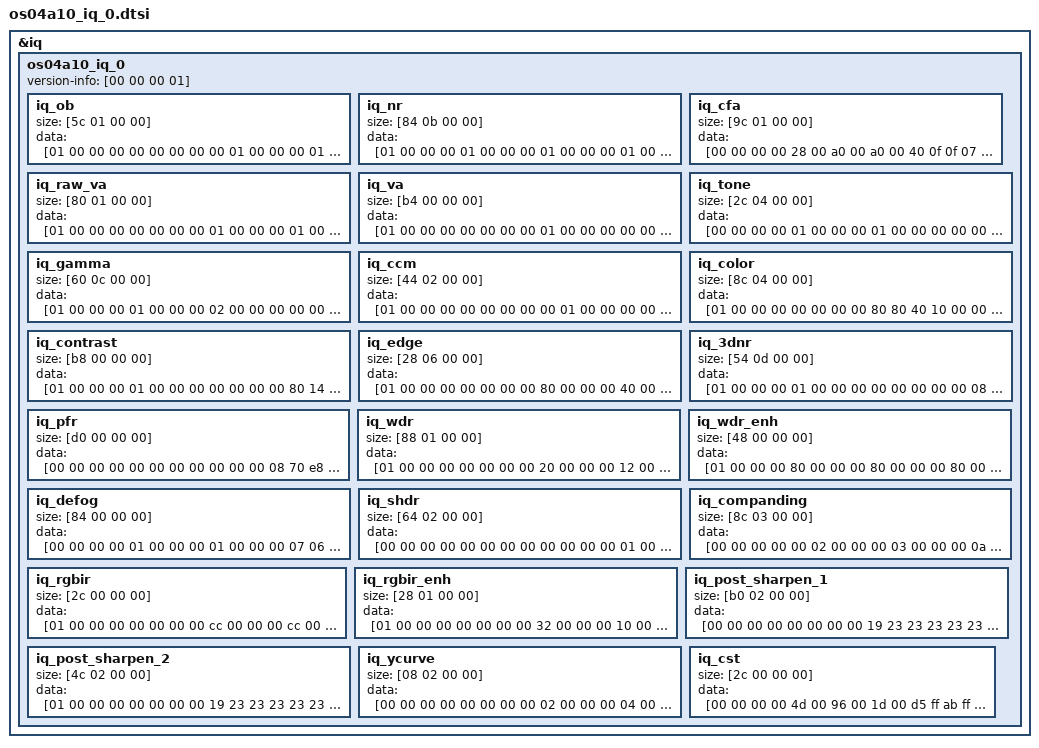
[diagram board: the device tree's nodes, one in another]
/*
 * Novatek Ltd. NVT98538 ISP part of dts
 */

&iq {
	os04a10_iq_0 {
		version-info = [00 00 00 01];
		iq_ob {
			size = [5c 01 00 00];
			data = [01 00 00 00 00 00 00 00 00 01 00 00 00 01 00 00 00 01 00 00 00 01 00 00 00 01 00 00 00 01 00 00 00 01 00 00 00 01 00 00 00 01 00 00 00 01 00 00 00 01 00 00 00 01 00 00 00 01 00 00 00 01 00 00 00 01 00 00 00 01 00 00 00 01 00 00 00 01 00 00 00 01 00 00 00 01 00 00 00 01 00 00 00 01 00 00 00 01 00 00 00 01 00 00 00 01 00 00 00 01 00 00 00 01 00 00 00 01 00 00 00 01 00 00 00 01 00 00 00 01 00 00 00 01 00 00 00 01 00 00 00 01 00 00 00 01 00 00 00 01 00 00 00 01 00 00 00 01 00 00 00 01 00 00 00 01 00 00 00 01 00 00 00 01 00 00 00 01 00 00 00 01 00 00 00 01 00 00 00 01 00 00 00 01 00 00 00 01 00 00 00 01 00 00 00 01 00 00 00 01 00 00 00 01 00 00 00 01 00 00 00 01 00 00 00 01 00 00 00 01 00 00 00 01 00 00 00 01 00 00 00 01 00 00 00 01 00 00 00 01 00 00 00 01 00 00 00 01 00 00 00 01 00 00 00 01 00 00 00 01 00 00 00 01 00 00 00 01 00 00 00 01 00 00 00 01 00 00 00 01 00 00 00 01 00 00 00 01 00 00 00 01 00 00 00 01 00 00 00 01 00 00 00 01 00 00 00 01 00 00 00 01 00 00 00 01 00 00 00 01 00 00 00 01 00 00 00 01 00 00 00 01 00 00 00 01 00 00];
		};
		iq_nr {
			size = [84 0b 00 00];
			data = [01 00 00 00 01 00 00 00 01 00 00 00 01 00 00 00 01 00 00 00 00 00 00 00 00 01 ff 00 00 00 00 00 00 00 00 00 ff 0f ff 0f ff 0f ff 0f ff 0f ff 0f ff 0f ff 0f ff 0f ff 0f 00 01 80 00 00 00 00 00 00 00 00 00 00 00 00 00 00 00 00 00 00 00 00 00 00 00 00 00 00 00 00 00 00 00 00 00 00 00 00 00 00 00 00 00 00 00 00 00 00 00 00 00 00 00 00 00 00 00 00 00 00 00 00 00 00 00 00 00 00 00 00 00 00 00 00 00 00 00 00 00 00 00 00 00 00 00 00 00 00 00 00 00 00 00 00 00 00 00 00 00 00 00 00 00 80 00 00 00 64 00 00 00 00 00 00 00 00 00 00 00 00 02 08 50 1e 02 01 03 01 01 00 00 02 00 00 00 02 00 00 00 00 01 ff 00 00 00 00 00 00 00 00 00 c6 02 0c 04 af 06 3d 09 41 0f c6 02 0c 04 af 06 3d 09 41 0f 00 00 80 00 00 00 00 00 00 00 00 00 01 00 01 00 01 00 02 00 00 00 02 00 02 00 03 00 04 00 04 00 04 00 05 00 05 00 06 00 06 00 06 00 06 00 07 00 07 00 07 00 08 00 00 00 00 00 03 00 03 00 03 00 06 00 00 00 02 00 02 00 03 00 04 00 04 00 04 00 05 00 05 00 06 00 06 00 06 00 06 00 07 00 07 00 07 00 08 00 00 00 40 00 80 00 00 00 64 00 00 00 00 00 00 00 00 00 00 00 00 02 08 50 00 04 06 03 01 01 00 00 00 00 00 00 00 00 00 00 00 01 ff 00 00 00 00 00 00 00 00 00 c6 02 0c 04 af 06 3d 09 41 0f c6 02 0c 04 af 06 3d 09 41 0f 00 00 80 00 00 00 00 00 00 00 02 00 02 00 03 00 04 00 05 00 00 00 02 00 03 00 04 00 04 00 05 00 05 00 06 00 06 00 07 00 07 00 07 00 08 00 08 00 08 00 09 00 09 00 00 00 06 00 06 00 09 00 0c 00 0f 00 00 00 02 00 03 00 04 00 04 00 05 00 05 00 06 00 06 00 07 00 07 00 07 00 08 00 08 00 08 00 09 00 09 00 00 00 40 00 80 00 00 00 64 00 00 00 00 00 00 00 00 00 00 00 00 02 08 50 00 06 0a 03 01 01 00 00 00 00 00 00 00 00 00 00 00 01 ff 00 00 00 00 00 00 00 00 00 c6 02 0c 04 af 06 3d 09 41 0f c6 02 0c 04 af 06 3d 09 41 0f 00 00 80 00 00 00 00 00 00 00 02 00 03 00 04 00 05 00 07 00 00 00 03 00 04 00 05 00 06 00 07 00 07 00 08 00 09 00 09 00 0a 00 0a 00 0b 00 0b 00 0b 00 0c 00 0c 00 00 00 06 00 09 00 0c 00 0f 00 15 00 00 00 03 00 04 00 05 00 06 00 07 00 07 00 08 00 09 00 09 00 0a 00 0a 00 0b 00 0b 00 0b 00 0c 00 0c 00 00 00 40 00 80 00 00 00 64 00 00 00 00 00 00 00 00 00 00 00 00 02 08 50 00 06 0a 03 01 01 00 00 00 00 00 00 00 00 00 00 00 01 ff 00 00 00 00 00 00 00 00 00 c6 02 0c 04 af 06 3d 09 41 0f c6 02 0c 04 af 06 3d 09 41 0f 09 00 80 00 00 00 00 00 00 00 02 00 03 00 04 00 05 00 07 00 00 00 04 00 05 00 06 00 08 00 08 00 09 00 0a 00 0b 00 0c 00 0c 00 0d 00 0d 00 0e 00 0e 00 0f 00 10 00 00 00 06 00 09 00 0c 00 0f 00 15 00 00 00 04 00 05 00 06 00 08 00 08 00 09 00 0a 00 0b 00 0c 00 0c 00 0d 00 0d 00 0e 00 0e 00 0f 00 10 00 00 00 20 00 80 00 00 00 64 00 00 00 00 00 00 00 00 00 00 00 00 02 08 50 00 06 0a 03 01 01 00 00 00 00 00 00 00 00 00 00 00 01 ff 00 00 00 00 00 00 00 00 00 c6 02 0c 04 af 06 3d 09 41 0f c6 02 0c 04 af 06 3d 09 41 0f 09 00 80 00 00 00 00 00 00 00 03 00 04 00 05 00 06 00 09 00 00 00 05 00 07 00 09 00 0b 00 0c 00 0d 00 0e 00 0f 00 10 00 11 00 12 00 13 00 14 00 14 00 15 00 16 00 00 00 09 00 0c 00 0f 00 12 00 1b 00 00 00 05 00 07 00 09 00 0b 00 0c 00 0d 00 0e 00 0f 00 10 00 11 00 12 00 13 00 14 00 14 00 15 00 16 00 00 00 20 00 6e 00 00 00 64 00 00 00 00 00 00 00 00 00 00 00 00 02 08 50 00 08 0c 03 01 01 00 00 00 00 00 00 00 00 00 00 00 01 ff 00 00 00 00 00 00 00 00 00 c6 02 0c 04 af 06 3d 09 41 0f c6 02 0c 04 af 06 3d 09 41 0f 09 00 80 00 00 00 00 00 00 00 04 00 06 00 07 00 08 00 0c 00 00 00 07 00 0a 00 0c 00 0e 00 10 00 11 00 13 00 14 00 15 00 16 00 17 00 18 00 19 00 1a 00 1b 00 1c 00 00 00 0c 00 12 00 15 00 18 00 24 00 00 00 07 00 0a 00 0c 00 0e 00 10 00 11 00 13 00 14 00 15 00 16 00 17 00 18 00 19 00 1a 00 1b 00 1c 00 00 00 20 00 6e 00 00 00 64 00 00 00 00 00 00 00 00 00 00 00 00 02 08 50 00 0a 10 03 01 01 00 00 00 00 00 00 01 00 00 00 00 01 ff 00 00 00 00 00 00 00 00 00 c6 02 0c 04 af 06 3d 09 41 0f c6 02 0c 04 af 06 3d 09 41 0f 09 00 80 00 00 00 00 00 00 00 06 00 09 00 0b 00 0c 00 12 00 00 00 05 00 0a 00 14 00 17 00 19 00 1c 00 1e 00 20 00 22 00 24 00 26 00 28 00 29 00 2b 00 2c 00 2e 00 00 00 12 00 1b 00 21 00 24 00 36 00 00 00 05 00 0a 00 14 00 17 00 19 00 1c 00 1e 00 20 00 22 00 24 00 26 00 28 00 29 00 2b 00 2c 00 2e 00 00 00 20 00 6e 00 00 00 64 00 00 00 00 00 00 00 00 00 00 00 00 02 08 50 00 0a 10 03 01 01 00 00 00 00 00 00 01 00 00 00 00 01 ff 00 00 00 00 00 00 00 00 00 c6 02 0c 04 af 06 3d 09 41 0f c6 02 0c 04 af 06 3d 09 41 0f 09 00 80 00 00 00 00 00 00 00 06 00 09 00 0b 00 0c 00 12 00 00 00 10 00 16 00 1b 00 20 00 23 00 27 00 2a 00 2d 00 30 00 32 00 35 00 37 00 39 00 3b 00 3d 00 40 00 00 00 13 00 1b 00 21 00 26 00 36 00 00 00 10 00 16 00 1b 00 20 00 23 00 27 00 2a 00 2d 00 30 00 32 00 35 00 37 00 39 00 3b 00 3d 00 40 00 00 00 20 00 6e 00 00 00 64 00 00 00 00 00 00 00 00 00 00 00 00 02 08 50 00 0a 10 03 01 01 00 00 01 00 00 00 02 00 00 00 00 01 ff 00 00 00 00 00 00 00 00 00 c6 02 0c 04 af 06 3d 09 41 0f c6 02 0c 04 af 06 3d 09 41 0f 09 00 80 00 00 00 00 00 00 00 0b 00 10 00 13 00 16 00 20 00 00 00 0f 00 1e 00 25 00 2b 00 30 00 34 00 39 00 3d 00 40 00 44 00 47 00 4a 00 4d 00 50 00 53 00 56 00 00 00 21 00 30 00 3b 00 42 00 60 00 00 00 0f 00 1e 00 25 00 2b 00 30 00 34 00 39 00 3d 00 40 00 44 00 47 00 4a 00 4d 00 50 00 53 00 56 00 00 00 20 00 64 00 00 00 64 00 00 00 00 00 00 00 00 00 00 00 00 05 14 28 02 0c 14 03 01 01 00 00 01 00 00 00 02 00 00 00 00 01 ff 00 00 00 00 00 00 00 00 00 c6 02 0c 04 af 06 3d 09 41 0f c6 02 0c 04 af 06 3d 09 41 0f 09 00 80 00 00 00 00 00 00 00 11 00 18 00 1e 00 23 00 31 00 00 00 12 00 19 00 1f 00 24 00 28 00 2c 00 2f 00 32 00 36 00 38 00 3b 00 3e 00 40 00 43 00 45 00 48 00 00 00 34 00 4a 00 5b 00 69 00 95 00 00 00 12 00 19 00 1f 00 24 00 28 00 2c 00 2f 00 32 00 36 00 38 00 3b 00 3e 00 40 00 43 00 45 00 48 00 08 00 14 00 40 00 00 00 90 01 00 00 00 00 00 00 00 00 00 00 00 0a 28 50 08 1c 20 03 01 01 00 00 01 00 00 00 02 00 00 00 00 01 ff 00 00 00 00 00 00 00 00 00 c6 02 0c 04 af 06 3d 09 41 0f c6 02 0c 04 af 06 3d 09 41 0f 5a 00 80 00 00 00 00 00 00 00 1a 00 25 00 2d 00 34 00 4a 00 00 00 17 00 20 00 28 00 2e 00 33 00 38 00 3d 00 41 00 45 00 49 00 4c 00 50 00 53 00 56 00 59 00 5c 00 00 00 49 00 67 00 7e 00 92 00 cf 00 00 00 1e 00 2a 00 33 00 3c 00 43 00 49 00 4f 00 54 00 5a 00 5e 00 63 00 67 00 6c 00 70 00 74 00 78 00 0a 00 0a 00 20 00 00 00 64 00 00 00 00 00 00 00 00 00 00 00 00 0a 28 50 0a 20 20 03 01 01 00 00 01 00 00 00 02 00 00 00 00 01 ff 00 00 00 00 00 00 00 00 00 c6 02 0c 04 af 06 3d 09 41 0f c6 02 0c 04 af 06 3d 09 41 0f 5a 00 80 00 00 00 00 00 00 00 2f 00 42 00 51 00 5e 00 85 00 00 00 24 00 34 00 3f 00 49 00 52 00 5a 00 61 00 68 00 6e 00 74 00 7a 00 7f 00 84 00 89 00 8e 00 93 00 00 00 8d 00 c7 00 f4 00 1a 01 8f 01 00 00 24 00 34 00 3f 00 49 00 52 00 5a 00 61 00 68 00 6e 00 74 00 7a 00 7f 00 84 00 89 00 8e 00 93 00 0c 00 0a 00 20 00 00 00 64 00 00 00 00 00 00 00 00 00 00 00 00 28 a0 f0 00 20 20 03 01 01 00 00 01 00 00 00 02 00 00 00 00 01 ff 00 00 00 00 00 00 00 00 00 c6 02 0c 04 af 06 3d 09 41 0f c6 02 0c 04 af 06 3d 09 41 0f 5a 00 80 00 00 00 00 00 00 00 2e 00 42 00 51 00 5d 00 84 00 00 00 32 00 47 00 57 00 65 00 71 00 7c 00 86 00 8f 00 98 00 a0 00 a8 00 af 00 b7 00 be 00 c4 00 cb 00 00 00 8a 00 c6 00 f3 00 17 01 8c 01 00 00 32 00 47 00 57 00 65 00 71 00 7c 00 86 00 8f 00 98 00 a0 00 a8 00 af 00 b7 00 be 00 c4 00 cb 00 0e 00 0a 00 20 00 00 00 64 00 00 00 00 00 00 00 00 00 00 00 00 02 08 50 00 20 20 03 01 01 00 00 01 00 00 00 02 00 00 00 00 01 ff 00 00 00 00 00 00 00 00 00 9a 01 53 02 d6 03 90 05 2e 09 9a 01 53 02 d6 03 90 05 2e 09 09 00 80 00 00 00 00 00 00 00 11 00 18 00 1e 00 23 00 31 00 00 00 30 00 43 00 53 00 60 00 6b 00 75 00 7e 00 87 00 90 00 97 00 9f 00 a6 00 ad 00 b3 00 b9 00 c0 00 00 00 33 00 48 00 5a 00 69 00 93 00 00 00 30 00 43 00 53 00 60 00 6b 00 75 00 7e 00 87 00 90 00 97 00 9f 00 a6 00 ad 00 b3 00 b9 00 c0 00 00 00 20 00 20 00 00 00 64 00 00 00 00 00 00 00 00 00 00 00 00 02 08 50 00 20 20 03 01 01 00 00 01 00 00 00 02 00 00 00 00 01 ff 00 00 00 00 00 00 00 00 00 9a 01 53 02 d6 03 90 05 2e 09 9a 01 53 02 d6 03 90 05 2e 09 09 00 80 00 00 00 00 00 00 00 11 00 18 00 1e 00 23 00 31 00 00 00 30 00 43 00 53 00 60 00 6b 00 75 00 7e 00 87 00 90 00 97 00 9f 00 a6 00 ad 00 b3 00 b9 00 c0 00 00 00 33 00 48 00 5a 00 69 00 93 00 00 00 30 00 43 00 53 00 60 00 6b 00 75 00 7e 00 87 00 90 00 97 00 9f 00 a6 00 ad 00 b3 00 b9 00 c0 00 00 00 20 00 20 00 00 00 64 00 00 00 00 00 00 00 00 00 00 00 00 02 08 50 00 20 20 03 01 01 00 00 01 00 00 00 02 00 00 00 00 01 ff 00 00 00 00 00 00 00 00 00 9a 01 53 02 d6 03 90 05 2e 09 9a 01 53 02 d6 03 90 05 2e 09 09 00 80 00 00 00 00 00 00 00 11 00 18 00 1e 00 23 00 31 00 00 00 30 00 43 00 53 00 60 00 6b 00 75 00 7e 00 87 00 90 00 97 00 9f 00 a6 00 ad 00 b3 00 b9 00 c0 00 00 00 33 00 48 00 5a 00 69 00 93 00 00 00 30 00 43 00 53 00 60 00 6b 00 75 00 7e 00 87 00 90 00 97 00 9f 00 a6 00 ad 00 b3 00 b9 00 c0 00 00 00 20 00 20 00 00 00 64 00 00 00 00 00 00 00 00 00 00 00 00 02 08 50 00 20 20 03 01 01 00 00 01 00 00 00 02 00 00 00];
		};
		iq_cfa {
			size = [9c 01 00 00];
			data = [00 00 00 00 28 00 a0 00 a0 00 40 0f 0f 07 04 03 02 02 01 01 01 01 00 00 00 00 00 00 28 00 a0 00 a0 00 40 0f 0f 07 04 03 02 02 01 01 01 01 00 00 00 00 00 00 28 00 a0 00 a0 00 40 0f 0f 07 04 03 02 02 01 01 01 01 00 00 00 00 00 00 28 00 a0 00 a0 00 40 0f 0f 07 04 03 02 02 01 01 01 01 00 00 00 00 00 00 28 00 a0 00 a0 00 40 0f 0f 07 04 03 02 02 01 01 01 01 00 00 00 00 00 00 28 00 a0 00 a0 00 40 0f 0f 07 04 03 02 02 01 01 01 01 00 00 00 00 00 00 28 00 a0 00 a0 00 40 0f 0f 07 04 03 02 02 01 01 01 01 00 00 00 00 00 00 28 00 a0 00 a0 00 40 0f 0f 07 04 03 02 02 01 01 01 01 00 00 00 00 00 00 28 00 a0 00 a0 00 40 0f 0f 07 04 03 02 02 01 01 01 01 00 00 00 00 00 00 28 00 a0 00 a0 00 40 0f 0f 07 04 03 02 02 01 01 01 01 00 00 00 00 00 00 28 00 a0 00 a0 00 40 0f 0f 07 04 03 02 02 01 01 01 01 00 00 00 00 00 00 28 00 a0 00 a0 00 20 08 08 03 02 01 01 01 00 00 00 00 00 00 00 00 00 00 28 00 a0 00 a0 00 20 08 08 03 02 01 01 01 00 00 00 00 00 00 00 00 00 00 28 00 a0 00 a0 00 40 0f 0f 07 04 03 02 02 01 01 01 01 00 00 00 00 00 00 28 00 a0 00 a0 00 40 0f 0f 07 04 03 02 02 01 01 01 01 00 00 00 00 00 00 28 00 a0 00 a0 00 40 0f 0f 07 04 03 02 02 01 01 01 01 00 00 00 00 00 00 28 00 a0 00 a0 00 40 0f 0f 07 04 03 02 02 01 01 01 01 00 00 00 00 00 00];
		};
		iq_raw_va {
			size = [80 01 00 00];
			data = [01 00 00 00 00 00 00 00 01 00 00 00 01 00 00 00 00 00 00 00 ff ff 00 00 03 00 00 00 01 00 00 00 00 00 00 00 02 00 00 00 ff ff 00 00 03 0a 96 ff ff 02 06 10 00 00 00 00 96 00 00 00 2c 00 a9 fe ca 00 06 00 00 00 2c 00 45 fe df 00 08 00 00 00 29 00 ae 00 00 00 08 00 00 00 00 00 00 00 2c 00 a9 fe ca 00 06 00 00 00 2c 00 45 fe df 00 08 00 00 00 29 00 ae 00 00 00 08 00 00 00 00 00 00 00 00 00 00 00 00 00 00 00 00 00 00 00 00 00 00 00 00 00 00 00 00 00 00 00 00 00 00 00 00 00 00 00 00 00 00 00 00 00 00 00 00 00 00 00 00 00 00 00 00 00 00 00 00 00 00 00 00 00 00 00 00 00 00 00 00 00 00 00 00 00 00 00 00 00 00 00 00 00 00 00 01 00 00 00 00 00 00 00 01 00 00 00 00 00 00 00 01 00 00 00 00 00 00 00 01 00 00 00 00 00 00 00 01 00 00 00 00 00 00 00 01 00 00 00 00 00 00 00 02 00 00 00 00 00 00 00 02 00 00 00 00 00 00 00 02 00 00 00 00 00 00 00 02 00 00 00 00 00 00 00 02 00 00 00 00 00 00 00 02 00 00 00 00 00 00 00 03 00 00 00 00 00 00 00 03 00 00 00 00 00 00 00 03 00 00 00 00 00 00 00 03 00 00 00 00 00 00 00 03 00 00 00 00 00 00 00 03 00 00 00 00 00 00 00 03 00 00 00 00 00 00 00 03 00 00 00 00 00 00 00 03 00 00 00 00 00 00 00 03 00 00 00 00 00 00 00];
		};
		iq_va {
			size = [b4 00 00 00];
			data = [01 00 00 00 00 00 00 00 01 00 00 00 00 00 ff 00 02 00 00 00 00 00 00 00 02 00 ff 00 03 0a 96 ff ff 02 06 10 00 00 00 00 96 00 00 00 00 00 00 00 00 00 00 00 00 00 00 00 00 00 00 00 00 00 00 00 00 00 00 00 00 00 00 00 00 00 00 00 00 00 00 00 00 00 00 00 00 00 00 00 00 00 00 00 00 00 00 00 00 00 00 00 00 00 00 00 00 00 00 00 00 00 00 00 00 00 00 00 00 00 00 00 00 00 00 00 00 00 00 00 00 00 00 00 00 00 00 00 00 00 00 00 00 00 00 00 00 00 00 00 00 00 00 00 00 00 00 00 00 00 00 00 00 00 00 00 00 00 00 00 00 00 00 00 00 00 00 00 00 00 00 00];
		};
		iq_tone {
			size = [2c 04 00 00];
			data = [00 00 00 00 01 00 00 00 01 00 00 00 00 00 00 00 00 00 00 00 00 00 00 00 8e 00 1c 01 aa 01 38 02 a9 02 1b 03 8c 03 fd 03 59 04 b5 04 11 05 6d 05 ba 05 06 06 53 06 9f 06 e0 06 20 07 61 07 a1 07 d8 07 0f 08 46 08 7d 08 ad 08 dd 08 0c 09 3c 09 66 09 90 09 b9 09 e3 09 08 0a 2d 0a 51 0a 76 0a 97 0a b7 0a d8 0a f8 0a 15 0b 33 0b 50 0b 6d 0b 88 0b a2 0b bd 0b d7 0b ef 0b 07 0c 1e 0c 36 0c 4c 0c 62 0c 77 0c 8d 0c a1 0c b5 0c c9 0c dd 0c ef 0c 02 0d 14 0d 26 0d 26 0d 6a 0d a8 0d e3 0d 1a 0e 4e 0e 7e 0e ac 0e d8 0e 02 0f 2a 0f 50 0f 75 0f 99 0f bc 0f de 0f ff 0f 00 00 00 00 00 00 00 00 e0 00 9e 01 43 02 d5 02 58 03 cf 03 3b 04 9e 04 03 05 5d 05 ab 05 ed 05 12 06 37 06 59 06 7a 06 93 06 ac 06 c5 06 de 06 f7 06 0f 07 27 07 40 07 58 07 6f 07 87 07 9f 07 b6 07 cd 07 e4 07 fc 07 13 08 2a 08 41 08 58 08 6e 08 85 08 9c 08 b2 08 c9 08 df 08 f5 08 0c 09 22 09 38 09 4e 09 64 09 7a 09 90 09 a6 09 bc 09 d2 09 e8 09 fe 09 13 0a 29 0a 3f 0a 54 0a 6a 0a 80 0a 95 0a ab 0a c0 0a c0 0a 16 0b 6c 0b c1 0b 16 0c 6a 0c bf 0c 13 0d 67 0d ba 0d 0e 0e 61 0e b4 0e 07 0f 5a 0f ad 0f ff 0f 19 00 00 00 00 00 57 01 59 02 27 03 d4 03 68 04 e9 04 5c 05 c4 05 2a 06 84 06 d1 06 12 07 35 07 57 07 77 07 96 07 ac 07 c2 07 d8 07 ef 07 04 08 1a 08 30 08 46 08 5b 08 70 08 85 08 9b 08 af 08 c4 08 d8 08 ed 08 01 09 16 09 2a 09 3e 09 52 09 66 09 7a 09 8e 09 a2 09 b6 09 c9 09 dd 09 f1 09 04 0a 18 0a 2b 0a 3f 0a 52 0a 66 0a 79 0a 8c 0a a0 0a b3 0a c6 0a d9 0a ec 0a ff 0a 13 0b 26 0b 39 0b 4c 0b 5f 0b 5f 0b aa 0b f6 0b 41 0c 8c 0c d6 0c 21 0d 6b 0d b5 0d ff 0d 48 0e 92 0e db 0e 24 0f 6e 0f b7 0f ff 0f 32 00 00 00 00 00 1e 02 69 03 58 04 14 05 ad 05 30 06 a2 06 06 07 67 07 bc 07 04 08 41 08 60 08 7e 08 9b 08 b6 08 c9 08 dd 08 f0 08 04 09 17 09 2a 09 3d 09 50 09 62 09 75 09 87 09 9a 09 ac 09 bd 09 cf 09 e1 09 f3 09 04 0a 16 0a 27 0a 39 0a 4a 0a 5b 0a 6c 0a 7e 0a 8f 0a a0 0a b1 0a c2 0a d3 0a e4 0a f5 0a 05 0b 16 0b 27 0b 38 0b 48 0b 59 0b 6a 0b 7a 0b 8b 0b 9c 0b ac 0b bd 0b cd 0b de 0b ee 0b fe 0b fe 0b 40 0c 81 0c c2 0c 03 0d 43 0d 84 0d c4 0d 04 0e 44 0e 83 0e c3 0e 03 0f 42 0f 81 0f c0 0f ff 0f 4b 00 00 00 00 00 69 02 c7 03 bb 04 77 05 11 06 92 06 01 07 64 07 c2 07 15 08 5b 08 96 08 b4 08 d1 08 ed 08 07 09 19 09 2c 09 3f 09 51 09 63 09 76 09 88 09 9a 09 ab 09 bd 09 ce 09 e0 09 f1 09 02 0a 13 0a 25 0a 36 0a 46 0a 57 0a 68 0a 79 0a 89 0a 9a 0a aa 0a bb 0a cb 0a db 0a ec 0a fc 0a 0c 0b 1c 0b 2c 0b 3d 0b 4d 0b 5d 0b 6d 0b 7d 0b 8d 0b 9d 0b ac 0b bc 0b cc 0b dc 0b ec 0b fc 0b 0b 0c 1b 0c 2b 0c 2b 0c 69 0c a8 0c e6 0c 24 0d 62 0d 9f 0d dd 0d 1a 0e 57 0e 94 0e d1 0e 0d 0f 4a 0f 87 0f c3 0f ff 0f 64 00 00 00 00 00 22 03 9b 04 93 05 4d 06 e1 06 5d 07 c7 07 23 08 7b 08 c8 08 0a 09 41 09 5c 09 77 09 90 09 a8 09 b9 09 ca 09 dc 09 ed 09 fd 09 0e 0a 1e 0a 2f 0a 3f 0a 4e 0a 5e 0a 6e 0a 7d 0a 8d 0a 9d 0a ad 0a bc 0a cb 0a db 0a ea 0a f9 0a 08 0b 17 0b 26 0b 35 0b 44 0b 53 0b 62 0b 70 0b 7f 0b 8e 0b 9c 0b ab 0b ba 0b c8 0b d7 0b e5 0b f4 0b 02 0c 11 0c 1f 0c 2e 0c 3c 0c 4a 0c 59 0c 67 0c 75 0c 84 0c 84 0c bd 0c f5 0c 2e 0d 66 0d 9e 0d d6 0d 0e 0e 46 0e 7d 0e b5 0e ec 0e 23 0f 5b 0f 92 0f c9 0f ff 0f 06 00 00 00 32 00 00 00 04 00 00 00 32 00 00 00 02 00 00 00 32 00 00 00 01 00 00 00 32 00 00 00 00 00 00 00 32 00 00 00];
		};
		iq_gamma {
			size = [60 0c 00 00];
			data = [01 00 00 00 01 00 00 00 02 00 00 00 00 00 00 00 25 00 00 00 49 00 00 00 6b 00 00 00 8b 00 00 00 a9 00 00 00 c6 00 00 00 e1 00 00 00 f1 00 00 00 01 01 00 00 11 01 00 00 21 01 00 00 30 01 00 00 3e 01 00 00 4d 01 00 00 5b 01 00 00 68 01 00 00 75 01 00 00 82 01 00 00 8f 01 00 00 9b 01 00 00 a6 01 00 00 b1 01 00 00 bc 01 00 00 c7 01 00 00 d1 01 00 00 db 01 00 00 e4 01 00 00 ed 01 00 00 f6 01 00 00 fe 01 00 00 06 02 00 00 0d 02 00 00 14 02 00 00 1b 02 00 00 22 02 00 00 29 02 00 00 30 02 00 00 36 02 00 00 3d 02 00 00 44 02 00 00 4b 02 00 00 52 02 00 00 59 02 00 00 5f 02 00 00 66 02 00 00 6d 02 00 00 73 02 00 00 7a 02 00 00 80 02 00 00 87 02 00 00 8d 02 00 00 93 02 00 00 9a 02 00 00 a0 02 00 00 a6 02 00 00 ac 02 00 00 b3 02 00 00 b9 02 00 00 bf 02 00 00 c5 02 00 00 cb 02 00 00 d1 02 00 00 d7 02 00 00 dd 02 00 00 e3 02 00 00 e8 02 00 00 ee 02 00 00 f4 02 00 00 fa 02 00 00 ff 02 00 00 04 03 00 00 09 03 00 00 0e 03 00 00 13 03 00 00 18 03 00 00 1d 03 00 00 21 03 00 00 26 03 00 00 2b 03 00 00 30 03 00 00 35 03 00 00 3a 03 00 00 3e 03 00 00 43 03 00 00 48 03 00 00 4d 03 00 00 51 03 00 00 56 03 00 00 5b 03 00 00 5f 03 00 00 64 03 00 00 68 03 00 00 6d 03 00 00 72 03 00 00 76 03 00 00 7b 03 00 00 7f 03 00 00 84 03 00 00 88 03 00 00 8c 03 00 00 91 03 00 00 95 03 00 00 99 03 00 00 9e 03 00 00 a2 03 00 00 a6 03 00 00 ab 03 00 00 af 03 00 00 b3 03 00 00 b7 03 00 00 bb 03 00 00 bf 03 00 00 c4 03 00 00 c8 03 00 00 cc 03 00 00 d0 03 00 00 d4 03 00 00 d8 03 00 00 dc 03 00 00 e0 03 00 00 e4 03 00 00 e8 03 00 00 eb 03 00 00 ef 03 00 00 f3 03 00 00 f7 03 00 00 fb 03 00 00 ff 03 00 00 00 00 00 00 00 00 00 00 08 00 00 00 10 00 00 00 18 00 00 00 20 00 00 00 28 00 00 00 30 00 00 00 38 00 00 00 40 00 00 00 48 00 00 00 50 00 00 00 58 00 00 00 60 00 00 00 68 00 00 00 70 00 00 00 78 00 00 00 80 00 00 00 88 00 00 00 90 00 00 00 98 00 00 00 a0 00 00 00 a8 00 00 00 b0 00 00 00 b8 00 00 00 c0 00 00 00 c8 00 00 00 d0 00 00 00 d8 00 00 00 e0 00 00 00 e8 00 00 00 f0 00 00 00 f8 00 00 00 00 01 00 00 08 01 00 00 10 01 00 00 18 01 00 00 20 01 00 00 28 01 00 00 30 01 00 00 38 01 00 00 40 01 00 00 48 01 00 00 50 01 00 00 58 01 00 00 60 01 00 00 68 01 00 00 70 01 00 00 78 01 00 00 80 01 00 00 88 01 00 00 90 01 00 00 98 01 00 00 a0 01 00 00 a8 01 00 00 b0 01 00 00 b8 01 00 00 c0 01 00 00 c8 01 00 00 d0 01 00 00 d8 01 00 00 e0 01 00 00 e8 01 00 00 f0 01 00 00 f7 01 00 00 ff 01 00 00 07 02 00 00 0f 02 00 00 17 02 00 00 1f 02 00 00 27 02 00 00 2f 02 00 00 37 02 00 00 3f 02 00 00 47 02 00 00 4f 02 00 00 57 02 00 00 5f 02 00 00 67 02 00 00 6f 02 00 00 77 02 00 00 7f 02 00 00 87 02 00 00 8f 02 00 00 97 02 00 00 9f 02 00 00 a7 02 00 00 af 02 00 00 b7 02 00 00 bf 02 00 00 c7 02 00 00 cf 02 00 00 d7 02 00 00 df 02 00 00 e7 02 00 00 ef 02 00 00 f7 02 00 00 ff 02 00 00 07 03 00 00 0f 03 00 00 17 03 00 00 1f 03 00 00 27 03 00 00 2f 03 00 00 37 03 00 00 3f 03 00 00 47 03 00 00 4f 03 00 00 57 03 00 00 5f 03 00 00 67 03 00 00 6f 03 00 00 77 03 00 00 7f 03 00 00 87 03 00 00 8f 03 00 00 97 03 00 00 9f 03 00 00 a7 03 00 00 af 03 00 00 b7 03 00 00 bf 03 00 00 c7 03 00 00 cf 03 00 00 d7 03 00 00 df 03 00 00 e7 03 00 00 ef 03 00 00 f7 03 00 00 ff 03 00 00 19 00 00 00 00 00 00 00 22 00 00 00 36 00 00 00 47 00 00 00 57 00 00 00 65 00 00 00 73 00 00 00 80 00 00 00 8c 00 00 00 98 00 00 00 a4 00 00 00 b0 00 00 00 bb 00 00 00 c6 00 00 00 d1 00 00 00 dc 00 00 00 e7 00 00 00 f1 00 00 00 fc 00 00 00 06 01 00 00 10 01 00 00 1b 01 00 00 25 01 00 00 2f 01 00 00 39 01 00 00 43 01 00 00 4d 01 00 00 57 01 00 00 60 01 00 00 6a 01 00 00 74 01 00 00 7d 01 00 00 87 01 00 00 90 01 00 00 9a 01 00 00 a3 01 00 00 ac 01 00 00 b6 01 00 00 bf 01 00 00 c8 01 00 00 d1 01 00 00 da 01 00 00 e3 01 00 00 ec 01 00 00 f5 01 00 00 fd 01 00 00 06 02 00 00 0f 02 00 00 17 02 00 00 20 02 00 00 28 02 00 00 30 02 00 00 39 02 00 00 41 02 00 00 49 02 00 00 51 02 00 00 59 02 00 00 61 02 00 00 69 02 00 00 71 02 00 00 78 02 00 00 80 02 00 00 88 02 00 00 8f 02 00 00 97 02 00 00 9e 02 00 00 a5 02 00 00 ad 02 00 00 b4 02 00 00 bb 02 00 00 c2 02 00 00 c9 02 00 00 d0 02 00 00 d7 02 00 00 dd 02 00 00 e4 02 00 00 eb 02 00 00 f1 02 00 00 f8 02 00 00 fe 02 00 00 05 03 00 00 0b 03 00 00 11 03 00 00 17 03 00 00 1e 03 00 00 24 03 00 00 2a 03 00 00 30 03 00 00 36 03 00 00 3b 03 00 00 41 03 00 00 47 03 00 00 4d 03 00 00 52 03 00 00 58 03 00 00 5d 03 00 00 63 03 00 00 68 03 00 00 6e 03 00 00 73 03 00 00 78 03 00 00 7d 03 00 00 83 03 00 00 88 03 00 00 8d 03 00 00 92 03 00 00 97 03 00 00 9c 03 00 00 a1 03 00 00 a6 03 00 00 ab 03 00 00 b0 03 00 00 b5 03 00 00 b9 03 00 00 be 03 00 00 c3 03 00 00 c8 03 00 00 cc 03 00 00 d1 03 00 00 d6 03 00 00 da 03 00 00 df 03 00 00 e4 03 00 00 e8 03 00 00 ed 03 00 00 f1 03 00 00 f6 03 00 00 fa 03 00 00 ff 03 00 00 32 00 00 00 00 00 00 00 25 00 00 00 49 00 00 00 6b 00 00 00 8b 00 00 00 a9 00 00 00 c6 00 00 00 e1 00 00 00 f1 00 00 00 01 01 00 00 11 01 00 00 21 01 00 00 30 01 00 00 3e 01 00 00 4d 01 00 00 5b 01 00 00 68 01 00 00 75 01 00 00 82 01 00 00 8f 01 00 00 9b 01 00 00 a6 01 00 00 b1 01 00 00 bc 01 00 00 c7 01 00 00 d1 01 00 00 db 01 00 00 e4 01 00 00 ed 01 00 00 f6 01 00 00 fe 01 00 00 06 02 00 00 0d 02 00 00 14 02 00 00 1b 02 00 00 22 02 00 00 29 02 00 00 30 02 00 00 36 02 00 00 3d 02 00 00 44 02 00 00 4b 02 00 00 52 02 00 00 59 02 00 00 5f 02 00 00 66 02 00 00 6d 02 00 00 73 02 00 00 7a 02 00 00 80 02 00 00 87 02 00 00 8d 02 00 00 93 02 00 00 9a 02 00 00 a0 02 00 00 a6 02 00 00 ac 02 00 00 b3 02 00 00 b9 02 00 00 bf 02 00 00 c5 02 00 00 cb 02 00 00 d1 02 00 00 d7 02 00 00 dd 02 00 00 e3 02 00 00 e8 02 00 00 ee 02 00 00 f4 02 00 00 fa 02 00 00 ff 02 00 00 04 03 00 00 09 03 00 00 0e 03 00 00 13 03 00 00 18 03 00 00 1d 03 00 00 21 03 00 00 26 03 00 00 2b 03 00 00 30 03 00 00 35 03 00 00 3a 03 00 00 3e 03 00 00 43 03 00 00 48 03 00 00 4d 03 00 00 51 03 00 00 56 03 00 00 5b 03 00 00 5f 03 00 00 64 03 00 00 68 03 00 00 6d 03 00 00 72 03 00 00 76 03 00 00 7b 03 00 00 7f 03 00 00 84 03 00 00 88 03 00 00 8c 03 00 00 91 03 00 00 95 03 00 00 99 03 00 00 9e 03 00 00 a2 03 00 00 a6 03 00 00 ab 03 00 00 af 03 00 00 b3 03 00 00 b7 03 00 00 bb 03 00 00 bf 03 00 00 c4 03 00 00 c8 03 00 00 cc 03 00 00 d0 03 00 00 d4 03 00 00 d8 03 00 00 dc 03 00 00 e0 03 00 00 e4 03 00 00 e8 03 00 00 eb 03 00 00 ef 03 00 00 f3 03 00 00 f7 03 00 00 fb 03 00 00 ff 03 00 00 4b 00 00 00 00 00 00 00 94 00 00 00 c3 00 00 00 e6 00 00 00 03 01 00 00 1c 01 00 00 33 01 00 00 48 01 00 00 5b 01 00 00 6d 01 00 00 7e 01 00 00 8e 01 00 00 9d 01 00 00 ac 01 00 00 ba 01 00 00 c7 01 00 00 d4 01 00 00 e0 01 00 00 ec 01 00 00 f8 01 00 00 03 02 00 00 0e 02 00 00 18 02 00 00 22 02 00 00 2c 02 00 00 36 02 00 00 3f 02 00 00 48 02 00 00 51 02 00 00 5a 02 00 00 62 02 00 00 6b 02 00 00 73 02 00 00 7b 02 00 00 82 02 00 00 8a 02 00 00 91 02 00 00 98 02 00 00 a0 02 00 00 a6 02 00 00 ad 02 00 00 b4 02 00 00 ba 02 00 00 c1 02 00 00 c7 02 00 00 cd 02 00 00 d3 02 00 00 d9 02 00 00 df 02 00 00 e5 02 00 00 ea 02 00 00 f0 02 00 00 f5 02 00 00 fb 02 00 00 00 03 00 00 05 03 00 00 0a 03 00 00 0f 03 00 00 14 03 00 00 19 03 00 00 1e 03 00 00 22 03 00 00 27 03 00 00 2c 03 00 00 30 03 00 00 35 03 00 00 39 03 00 00 3d 03 00 00 42 03 00 00 46 03 00 00 4a 03 00 00 4e 03 00 00 52 03 00 00 56 03 00 00 5a 03 00 00 5e 03 00 00 62 03 00 00 66 03 00 00 69 03 00 00 6d 03 00 00 71 03 00 00 74 03 00 00 78 03 00 00 7b 03 00 00 7f 03 00 00 82 03 00 00 86 03 00 00 89 03 00 00 8d 03 00 00 90 03 00 00 93 03 00 00 97 03 00 00 9a 03 00 00 9d 03 00 00 a0 03 00 00 a3 03 00 00 a6 03 00 00 aa 03 00 00 ad 03 00 00 b0 03 00 00 b3 03 00 00 b6 03 00 00 b9 03 00 00 bc 03 00 00 bf 03 00 00 c1 03 00 00 c4 03 00 00 c7 03 00 00 ca 03 00 00 cd 03 00 00 d0 03 00 00 d2 03 00 00 d5 03 00 00 d8 03 00 00 db 03 00 00 dd 03 00 00 e0 03 00 00 e3 03 00 00 e5 03 00 00 e8 03 00 00 eb 03 00 00 ed 03 00 00 f0 03 00 00 f2 03 00 00 f5 03 00 00 f7 03 00 00 fa 03 00 00 fc 03 00 00 ff 03 00 00 64 00 00 00 00 00 00 00 d2 00 00 00 09 01 00 00 31 01 00 00 52 01 00 00 6d 01 00 00 85 01 00 00 9b 01 00 00 af 01 00 00 c1 01 00 00 d2 01 00 00 e2 01 00 00 f1 01 00 00 00 02 00 00 0d 02 00 00 1a 02 00 00 26 02 00 00 31 02 00 00 3d 02 00 00 47 02 00 00 52 02 00 00 5b 02 00 00 65 02 00 00 6e 02 00 00 77 02 00 00 80 02 00 00 88 02 00 00 90 02 00 00 98 02 00 00 9f 02 00 00 a7 02 00 00 ae 02 00 00 b5 02 00 00 bc 02 00 00 c2 02 00 00 c9 02 00 00 cf 02 00 00 d5 02 00 00 db 02 00 00 e1 02 00 00 e7 02 00 00 ed 02 00 00 f2 02 00 00 f8 02 00 00 fd 02 00 00 02 03 00 00 07 03 00 00 0c 03 00 00 11 03 00 00 16 03 00 00 1b 03 00 00 1f 03 00 00 24 03 00 00 28 03 00 00 2c 03 00 00 31 03 00 00 35 03 00 00 39 03 00 00 3d 03 00 00 41 03 00 00 45 03 00 00 49 03 00 00 4d 03 00 00 51 03 00 00 54 03 00 00 58 03 00 00 5c 03 00 00 5f 03 00 00 63 03 00 00 66 03 00 00 6a 03 00 00 6d 03 00 00 70 03 00 00 74 03 00 00 77 03 00 00 7a 03 00 00 7d 03 00 00 81 03 00 00 84 03 00 00 87 03 00 00 8a 03 00 00 8d 03 00 00 90 03 00 00 93 03 00 00 96 03 00 00 98 03 00 00 9b 03 00 00 9e 03 00 00 a1 03 00 00 a4 03 00 00 a6 03 00 00 a9 03 00 00 ac 03 00 00 ae 03 00 00 b1 03 00 00 b4 03 00 00 b6 03 00 00 b9 03 00 00 bb 03 00 00 be 03 00 00 c0 03 00 00 c3 03 00 00 c5 03 00 00 c8 03 00 00 ca 03 00 00 cc 03 00 00 cf 03 00 00 d1 03 00 00 d3 03 00 00 d6 03 00 00 d8 03 00 00 da 03 00 00 dd 03 00 00 df 03 00 00 e1 03 00 00 e3 03 00 00 e6 03 00 00 e8 03 00 00 ea 03 00 00 ec 03 00 00 ee 03 00 00 f0 03 00 00 f2 03 00 00 f5 03 00 00 f7 03 00 00 f9 03 00 00 fb 03 00 00 fd 03 00 00 ff 03 00 00 06 00 00 00 32 00 00 00 04 00 00 00 32 00 00 00 02 00 00 00 32 00 00 00 01 00 00 00 32 00 00 00 00 00 00 00 32 00 00 00];
		};
		iq_ccm {
			size = [44 02 00 00];
			data = [01 00 00 00 00 00 00 00 00 01 00 00 00 00 00 00 00 01 00 00 00 00 00 00 00 01 80 80 80 80 80 80 80 80 80 80 80 80 80 80 80 80 80 80 80 80 80 80 80 80 00 00 00 00 00 00 00 00 00 00 00 00 00 00 00 00 00 00 00 00 00 00 00 00 00 00 00 00 00 00 00 00 00 00 00 00 00 00 00 00 00 00 00 00 00 00 00 00 00 00 64 19 00 00 6a 01 e4 ff b3 ff 8e ff fe 01 75 ff 0a 00 4a ff ab 01 80 80 80 80 80 80 80 80 80 80 80 80 80 80 80 80 80 80 80 80 80 80 80 80 00 00 00 00 00 00 00 00 00 00 00 00 00 00 00 00 00 00 00 00 00 00 00 00 00 00 00 00 00 00 00 00 00 00 00 00 00 00 00 00 00 00 00 00 00 00 00 00 00 00 74 0e 00 00 67 01 dc ff bd ff 59 ff ee 01 b9 ff 14 00 33 ff b9 01 80 80 80 80 80 80 80 80 80 80 80 80 80 80 80 80 80 80 80 80 80 80 80 80 00 00 00 00 00 00 00 00 00 00 00 00 00 00 00 00 00 00 00 00 00 00 00 00 00 00 00 00 00 00 00 00 00 00 00 00 00 00 00 00 00 00 00 00 00 00 00 00 00 00 f0 0a 00 00 f6 00 7e 00 8c ff 48 ff 12 02 a6 ff f3 ff 17 ff f6 01 80 80 80 80 80 80 80 80 80 80 80 80 80 80 80 80 80 80 80 80 80 80 80 80 00 00 00 00 00 00 00 00 00 00 00 00 00 00 00 00 00 00 00 00 00 00 00 00 00 00 00 00 00 00 00 00 00 00 00 00 00 00 00 00 00 00 00 00 00 00 00 00 00 00 f0 0a 00 00 f6 00 7e 00 8c ff 48 ff 12 02 a6 ff f3 ff 17 ff f6 01 80 80 80 80 80 80 80 80 80 80 80 80 80 80 80 80 80 80 80 80 80 80 80 80 00 00 00 00 00 00 00 00 00 00 00 00 00 00 00 00 00 00 00 00 00 00 00 00 00 00 00 00 00 00 00 00 00 00 00 00 00 00 00 00 00 00 00 00 00 00 00 00 00 00 f0 0a 00 00 f6 00 7e 00 8c ff 48 ff 12 02 a6 ff f3 ff 17 ff f6 01 80 80 80 80 80 80 80 80 80 80 80 80 80 80 80 80 80 80 80 80 80 80 80 80 00 00 00 00 00 00 00 00 00 00 00 00 00 00 00 00 00 00 00 00 00 00 00 00 00 00 00 00 00 00 00 00 00 00 00 00 00 00 00 00 00 00 00 00 00 00 00 00 00 00];
		};
		iq_color {
			size = [8c 04 00 00];
			data = [01 00 00 00 00 00 00 00 80 80 40 10 00 00 00 00 00 00 00 00 00 00 00 00 00 14 0f 0a 05 00 00 00 00 00 00 00 00 00 05 0a 0f 00 80 00 80 00 80 00 80 00 80 00 80 00 80 00 80 00 80 00 80 00 80 00 80 00 80 00 80 00 80 00 80 00 80 00 80 80 40 10 00 00 00 00 00 00 00 00 00 00 00 00 00 14 0f 0a 05 00 00 00 00 00 00 00 00 00 05 0a 0f 00 80 00 80 00 80 00 80 00 80 00 80 00 80 00 80 00 80 00 80 00 80 00 80 00 80 00 80 00 80 00 80 00 80 00 80 80 40 10 00 00 00 00 00 00 00 00 00 00 00 00 00 14 0f 0a 05 00 00 00 00 00 00 00 00 00 05 0a 0f 00 80 00 80 00 80 00 80 00 80 00 80 00 80 00 80 00 80 00 80 00 80 00 80 00 80 00 80 00 80 00 80 00 80 00 80 80 40 10 00 00 00 00 00 00 00 00 00 00 00 00 00 14 0f 0a 05 00 00 00 00 00 00 00 00 00 05 0a 0f 00 80 00 80 00 80 00 80 00 80 00 80 00 80 00 80 00 80 00 80 00 80 00 80 00 80 00 80 00 80 00 80 00 80 00 80 80 40 10 00 00 00 00 00 00 00 00 00 00 00 00 00 14 0f 0a 05 00 00 00 00 00 00 00 00 00 05 0a 0f 00 80 00 80 00 80 00 80 00 80 00 80 00 80 00 80 00 80 00 80 00 80 00 80 00 80 00 80 00 80 00 80 00 80 00 80 80 40 10 00 00 00 00 00 00 00 00 00 00 00 00 00 14 0f 0a 05 00 00 00 00 00 00 00 00 00 05 0a 0f 00 80 00 80 00 80 00 80 00 80 00 80 00 80 00 80 00 80 00 80 00 80 00 80 00 80 00 80 00 80 00 80 00 80 00 80 80 40 10 00 00 00 00 00 00 00 00 00 00 00 00 00 14 0f 0a 05 00 00 00 00 00 00 00 00 00 05 0a 0f 00 80 00 80 00 80 00 80 00 80 00 80 00 80 00 80 00 80 00 80 00 80 00 80 00 80 00 80 00 80 00 80 00 80 00 80 80 40 10 00 00 00 00 00 00 00 00 00 00 00 00 00 14 0f 0a 05 00 00 00 00 00 00 00 00 00 05 0a 0f 00 80 00 80 00 80 00 80 00 80 00 80 00 80 00 80 00 80 00 80 00 80 00 80 00 80 00 80 00 80 00 80 00 80 00 80 80 40 10 00 00 00 00 00 00 00 00 00 00 00 00 00 14 0f 0a 05 00 00 00 00 00 00 00 00 00 05 0a 0f 00 80 00 80 00 80 00 80 00 80 00 80 00 80 00 80 00 80 00 80 00 80 00 80 00 80 00 80 00 80 00 80 00 80 00 80 80 40 10 00 00 00 00 00 00 00 00 00 00 00 00 00 14 0f 0a 05 00 00 00 00 00 00 00 00 00 05 0a 0f 00 80 00 80 00 80 00 80 00 80 00 80 00 80 00 80 00 80 00 80 00 80 00 80 00 80 00 80 00 80 00 80 00 80 00 80 80 40 10 00 00 00 00 00 00 00 00 00 00 00 00 00 14 0f 0a 05 00 00 00 00 00 00 00 00 00 05 0a 0f 00 46 00 50 00 5a 00 64 00 6e 00 80 00 8c 00 a0 00 b4 00 c8 00 c8 00 c8 00 c8 00 c8 00 b4 00 a0 00 80 00 80 80 40 10 00 00 00 00 00 00 00 00 00 00 00 00 00 14 0f 0a 05 00 00 00 00 00 00 00 00 00 05 0a 0f 00 1e 00 1e 00 28 00 32 00 3c 00 46 00 5a 00 80 00 a0 00 a0 00 a0 00 a0 00 a0 00 a0 00 a0 00 8c 00 80 00 80 80 40 10 00 00 00 00 00 00 00 00 00 00 00 00 00 14 0f 0a 05 00 00 00 00 00 00 00 00 00 05 0a 0f 00 1e 00 1e 00 28 00 32 00 3c 00 46 00 5a 00 80 00 a0 00 a0 00 a0 00 a0 00 a0 00 a0 00 a0 00 8c 00 80 00 80 80 40 10 00 00 00 00 00 00 00 00 00 00 00 00 00 14 0f 0a 05 00 00 00 00 00 00 00 00 00 05 0a 0f 00 80 00 80 00 80 00 80 00 80 00 80 00 80 00 80 00 80 00 80 00 80 00 80 00 80 00 80 00 80 00 80 00 80 00 80 80 40 10 00 00 00 00 00 00 00 00 00 00 00 00 00 14 0f 0a 05 00 00 00 00 00 00 00 00 00 05 0a 0f 00 80 00 80 00 80 00 80 00 80 00 80 00 80 00 80 00 80 00 80 00 80 00 80 00 80 00 80 00 80 00 80 00 80 00 80 80 40 10 00 00 00 00 00 00 00 00 00 00 00 00 00 14 0f 0a 05 00 00 00 00 00 00 00 00 00 05 0a 0f 00 80 00 80 00 80 00 80 00 80 00 80 00 80 00 80 00 80 00 80 00 80 00 80 00 80 00 80 00 80 00 80 00 80 00 80 80 40 10 00 00 00 00 00 00 00 00 00 00 00 00 00 14 0f 0a 05 00 00 00 00 00 00 00 00 00 05 0a 0f 00 80 00 80 00 80 00 80 00 80 00 80 00 80 00 80 00 80 00 80 00 80 00 80 00 80 00 80 00 80 00 80 00 80 00];
		};
		iq_contrast {
			size = [b8 00 00 00];
			data = [01 00 00 00 01 00 00 00 00 00 00 00 80 14 14 14 14 14 14 14 14 14 80 14 14 14 14 14 14 14 14 14 80 14 14 14 14 14 14 14 14 14 80 14 14 14 14 14 14 14 14 14 80 14 14 14 14 14 14 14 14 14 80 14 14 14 14 14 14 14 14 14 80 14 14 14 14 14 14 14 14 14 80 14 14 14 14 14 14 14 14 14 80 14 14 14 14 14 14 14 14 14 80 14 14 14 14 14 14 14 14 14 80 14 14 14 14 14 14 14 14 14 80 0a 0a 0a 0a 0a 0a 0a 0a 0a 80 0a 0a 0a 0a 0a 0a 0a 0a 0a 80 0a 0a 0a 0a 0a 0a 0a 0a 0a 80 0a 0a 0a 0a 0a 0a 0a 0a 0a 80 0a 0a 0a 0a 0a 0a 0a 0a 0a 80 0a 0a 0a 0a 0a 0a 0a 0a 0a 00 00];
		};
		iq_edge {
			size = [28 06 00 00];
			data = [01 00 00 00 00 00 00 00 80 00 00 00 40 00 00 00 32 e0 10 64 78 8c a0 b4 c8 e0 ff ff e0 c0 aa 9a 90 88 80 20 2d 35 40 40 40 40 40 40 40 40 40 40 35 2d 20 80 80 80 80 80 80 80 80 80 80 80 80 80 80 80 80 80 80 80 80 80 80 80 80 00 40 00 00 00 80 00 00 00 80 00 00 00 08 00 00 00 00 00 00 00 00 00 00 00 10 00 00 00 08 00 00 00 28 00 00 00 f0 00 00 00 00 01 00 00 20 50 00 00 00 01 00 00 00 01 00 00 00 00 00 00 80 00 00 00 00 00 00 00 02 00 00 00 00 00 00 00 00 02 00 00 00 00 00 00 05 00 00 00 04 00 00 00 8c 00 00 00 8c 00 00 00 10 00 00 00 10 00 00 00 00 00 00 00 10 00 00 00 14 00 00 00 28 00 00 00 5a 00 00 00 6e 00 00 00 20 50 00 00 00 01 00 00 00 01 00 00 00 00 00 00 80 00 00 00 00 00 00 00 05 00 00 00 00 00 00 00 00 02 00 00 00 00 00 00 05 00 00 00 04 00 00 00 8c 00 00 00 8c 00 00 00 10 00 00 00 10 00 00 00 00 00 00 00 10 00 00 00 1e 00 00 00 32 00 00 00 64 00 00 00 78 00 00 00 20 50 00 00 00 01 00 00 00 01 00 00 00 00 00 00 80 00 00 00 00 00 00 00 05 00 00 00 00 00 00 00 00 02 00 00 00 00 00 00 05 00 00 00 04 00 00 00 8c 00 00 00 8c 00 00 00 10 00 00 00 0c 00 00 00 00 00 00 00 10 00 00 00 28 00 00 00 3c 00 00 00 6e 00 00 00 82 00 00 00 20 50 00 00 00 01 00 00 00 01 00 00 00 00 00 00 80 00 00 00 00 00 00 00 04 00 00 00 00 00 00 00 00 02 00 00 00 00 00 00 05 00 00 00 04 00 00 00 8c 00 00 00 8c 00 00 00 0c 00 00 00 08 00 00 00 00 00 00 00 0c 00 00 00 3c 00 00 00 50 00 00 00 82 00 00 00 96 00 00 00 20 50 00 00 00 01 00 00 00 01 00 00 00 00 00 00 80 00 00 00 00 00 00 00 04 00 00 00 00 00 00 00 00 02 00 00 00 00 00 00 05 00 00 00 04 00 00 00 8c 00 00 00 8c 00 00 00 08 00 00 00 08 00 00 00 00 00 00 00 08 00 00 00 50 00 00 00 64 00 00 00 96 00 00 00 aa 00 00 00 20 50 00 00 00 01 00 00 00 01 00 00 00 00 00 00 80 00 00 00 00 00 00 00 04 00 00 00 00 00 00 00 00 02 00 00 00 00 00 00 05 00 00 00 04 00 00 00 8c 00 00 00 8c 00 00 00 08 00 00 00 08 00 00 00 00 00 00 00 08 00 00 00 78 00 00 00 8c 00 00 00 c8 00 00 00 dc 00 00 00 20 50 00 00 00 01 00 00 00 01 00 00 00 00 00 00 80 00 00 00 00 00 00 00 04 00 00 00 00 00 00 00 00 02 00 00 00 00 00 00 05 00 00 00 04 00 00 00 8c 00 00 00 8c 00 00 00 06 00 00 00 06 00 00 00 00 00 00 00 08 00 00 00 8c 00 00 00 a0 00 00 00 d2 00 00 00 e6 00 00 00 20 50 00 00 00 01 00 00 00 01 00 00 00 00 00 00 80 00 00 00 00 00 00 00 04 00 00 00 00 00 00 00 00 02 00 00 00 00 00 00 05 00 00 00 04 00 00 00 82 00 00 00 82 00 00 00 04 00 00 00 04 00 00 00 00 00 00 00 04 00 00 00 64 00 00 00 c8 00 00 00 2c 01 00 00 dc 00 00 00 20 50 00 00 00 01 00 00 00 01 00 00 00 00 00 00 80 00 00 00 02 00 00 00 02 00 00 00 00 00 00 00 00 02 00 00 00 00 00 00 05 00 00 00 04 00 00 00 6e 00 00 00 6e 00 00 00 02 00 00 00 02 00 00 00 00 00 00 00 04 00 00 00 fa 00 00 00 0e 01 00 00 68 01 00 00 7c 01 00 00 20 50 00 00 00 01 00 00 00 01 00 00 00 00 00 00 80 00 00 00 02 00 00 00 02 00 00 00 00 00 00 00 00 02 00 00 00 00 00 00 05 00 00 00 04 00 00 00 64 00 00 00 64 00 00 00 00 00 00 00 00 00 00 00 00 00 00 00 04 00 00 00 7c 01 00 00 90 01 00 00 e0 01 00 00 ea 01 00 00 14 50 00 00 00 01 00 00 00 01 00 00 00 00 00 00 80 00 00 00 03 00 00 00 02 00 00 00 00 00 00 00 00 02 00 00 00 00 00 00 05 00 00 00 04 00 00 00 64 00 00 00 64 00 00 00 00 00 00 00 00 00 00 00 00 00 00 00 04 00 00 00 f4 01 00 00 08 02 00 00 3a 02 00 00 4e 02 00 00 14 50 00 00 00 01 00 00 00 01 00 00 00 00 00 00 80 00 00 00 03 00 00 00 02 00 00 00 00 00 00 00 00 02 00 00 00 00 00 00 05 00 00 00 04 00 00 00 5a 00 00 00 5a 00 00 00 00 00 00 00 00 00 00 00 00 00 00 00 04 00 00 00 44 02 00 00 58 02 00 00 d0 02 00 00 d0 02 00 00 14 50 00 00 00 01 00 00 00 01 00 00 00 00 00 00 80 00 00 00 03 00 00 00 02 00 00 00 00 00 00 00 00 02 00 00 00 00 00 00 05 00 00 00 04 00 00 00 5a 00 00 00 5a 00 00 00 00 00 00 00 00 00 00 00 00 00 00 00 04 00 00 00 70 03 00 00 84 03 00 00 e8 03 00 00 fc 03 00 00 14 50 00 00 00 01 00 00 00 01 00 00 00 00 00 00 80 00 00 00 03 00 00 00 02 00 00 00 00 00 00 00 00 02 00 00 00 00 00 00 05 00 00 00 04 00 00 00 5a 00 00 00 5a 00 00 00 00 00 00 00 00 00 00 00 00 00 00 00 04 00 00 00 44 02 00 00 58 02 00 00 bc 02 00 00 d0 02 00 00 14 50 00 00 00 01 00 00 00 01 00 00 00 00 00 00 80 00 00 00 03 00 00 00 02 00 00 00 00 00 00 00 00 02 00 00 00 00 00 00 05 00 00 00 04 00 00 00 50 00 00 00 50 00 00 00 00 00 00 00 00 00 00 00 00 00 00 00 04 00 00 00 44 02 00 00 58 02 00 00 bc 02 00 00 d0 02 00 00 14 50 00 00 00 01 00 00 00 01 00 00 00 00 00 00 80 00 00 00 03 00 00 00 02 00 00 00 00 00 00 00 00 02 00 00 00 00 00 00 05 00 00 00 04 00 00 00 46 00 00 00 46 00 00 00 00 00 00 00 00 00 00 00 00 00 00 00 04 00 00 00 44 02 00 00 58 02 00 00 bc 02 00 00 d0 02 00 00 14 50 00 00 00 01 00 00 00 01 00 00 00 00 00 00 80 00 00 00 03 00 00 00 02 00 00 00 00 00 00 00 00 02 00 00 00 00 00 00 05 00 00 00 04 00 00 00];
		};
		iq_3dnr {
			size = [54 0d 00 00];
			data = [01 00 00 00 01 00 00 00 00 00 00 00 00 08 40 00 40 00 00 00 80 00 80 00 80 00 c8 00 c8 00 04 04 03 04 04 04 04 04 05 05 06 06 07 07 08 08 80 04 00 00 00 00 00 00 00 00 00 00 00 00 00 00 00 00 00 00 00 00 00 00 00 00 00 00 00 00 00 00 00 00 00 00 00 00 00 00 00 00 00 00 00 00 00 00 00 00 00 00 00 00 00 00 00 00 08 10 04 10 20 06 c8 00 01 01 01 01 00 00 00 00 00 00 00 00 00 00 00 00 00 00 10 20 30 40 80 40 00 01 00 00 00 01 00 00 10 10 10 10 10 10 10 10 10 10 10 10 08 10 40 40 10 08 00 06 0c 18 28 4c 60 70 80 40 00 06 0c 18 28 4c 60 70 80 40 00 04 01 ff 40 00 40 00 40 00 40 00 40 00 40 00 40 00 40 00 00 00 00 00 00 00 00 00 00 00 00 08 14 00 14 00 00 00 28 00 28 00 28 00 3c 00 3c 00 04 04 03 04 04 04 04 04 06 06 06 06 06 07 07 08 80 08 64 00 64 00 64 00 c8 00 c8 00 c8 00 2c 01 2c 01 07 07 07 07 07 07 06 06 32 00 28 00 28 00 28 00 1e 00 1e 00 1e 00 1e 00 19 00 19 00 19 00 19 00 19 00 19 00 19 00 19 00 08 10 03 00 3f 03 bc 02 01 01 01 01 00 20 20 00 08 04 02 04 02 01 00 00 00 00 04 08 10 20 80 40 f4 01 00 00 f4 01 00 00 10 10 20 20 10 10 10 10 10 10 10 10 00 14 32 96 20 00 00 10 20 30 40 50 60 70 80 40 00 10 20 30 40 50 60 70 80 40 00 04 01 ff 40 00 40 00 40 00 40 00 40 00 40 00 40 00 40 00 00 00 00 00 00 00 00 00 00 00 00 08 28 00 28 00 00 00 50 00 50 00 50 00 78 00 78 00 04 04 03 04 04 04 04 04 06 06 06 06 06 07 07 08 80 08 64 00 64 00 64 00 c8 00 c8 00 c8 00 b8 0b 2c 01 08 08 08 08 07 07 07 07 3c 00 32 00 32 00 32 00 28 00 28 00 28 00 28 00 25 00 25 00 25 00 25 00 25 00 20 00 20 00 20 00 08 10 03 00 3f 03 20 03 01 01 01 01 20 40 40 00 08 04 02 04 02 01 00 00 00 00 04 08 10 20 80 40 f4 01 00 00 f4 01 00 00 10 10 20 20 10 10 10 10 10 10 10 10 00 14 32 96 20 00 00 10 20 30 40 50 60 70 80 40 00 10 20 30 40 50 60 70 80 40 00 04 01 ff 40 00 40 00 40 00 40 00 40 00 40 00 40 00 40 00 00 00 00 00 00 00 00 00 00 00 00 08 32 00 32 00 00 00 64 00 64 00 64 00 96 00 96 00 04 04 03 04 04 04 04 04 06 06 06 06 06 07 07 08 80 08 64 00 64 00 64 00 c8 00 c8 00 c8 00 b8 0b 2c 01 09 09 09 09 08 08 08 08 46 00 3c 00 3c 00 3c 00 32 00 32 00 32 00 32 00 28 00 28 00 28 00 28 00 28 00 23 00 23 00 23 00 08 10 03 00 3f 03 84 03 01 01 01 01 20 40 40 00 08 04 02 04 02 01 00 00 00 00 04 08 10 20 80 40 f4 01 00 00 f4 01 00 00 10 10 20 20 10 10 10 10 10 10 10 10 00 14 32 96 20 10 00 10 20 30 40 50 60 70 80 40 00 10 20 30 40 50 60 70 80 40 00 04 01 ff 40 00 40 00 40 00 40 00 40 00 40 00 40 00 40 00 00 00 00 00 00 00 00 00 00 00 05 08 3c 00 3c 00 00 00 78 00 78 00 78 00 b4 00 b4 00 04 04 03 04 04 04 04 04 06 06 06 06 06 07 07 08 80 08 64 00 64 00 64 00 c8 00 c8 00 c8 00 b8 0b 2c 01 0b 0b 0b 0b 0a 0a 0a 0a 50 00 46 00 46 00 46 00 3c 00 3c 00 3c 00 3c 00 32 00 32 00 37 00 37 00 37 00 32 00 32 00 32 00 08 10 03 00 3f 03 e8 03 01 01 01 01 20 40 40 00 0c 06 03 04 02 01 00 00 00 00 04 08 10 20 80 40 58 02 00 00 58 02 00 00 10 10 20 20 10 10 10 10 10 10 10 10 00 14 32 96 20 08 00 0a 14 1e 2b 41 4e 61 80 40 00 0e 1c 2b 39 47 55 66 80 40 00 04 01 ff 40 00 40 00 40 00 40 00 40 00 40 00 40 00 40 00 00 00 00 00 00 00 00 00 00 00 0a 08 50 00 50 00 00 00 a0 00 a0 00 a0 00 f0 00 f0 00 04 04 03 04 04 04 04 04 06 06 06 06 06 07 07 08 80 08 64 00 64 00 64 00 c8 00 c8 00 c8 00 2c 01 2c 01 0c 0c 0c 0c 0c 0c 0b 0a 64 00 64 00 64 00 64 00 64 00 64 00 64 00 64 00 3c 00 3c 00 3c 00 3c 00 3c 00 3c 00 37 00 37 00 08 10 03 05 3f 03 4c 04 01 01 01 01 10 ff ff 00 10 08 04 08 04 02 00 00 00 00 10 20 40 50 80 40 20 03 00 00 20 03 00 00 10 10 20 20 10 10 10 10 10 10 10 10 00 1e 32 80 40 10 00 0a 14 1e 2f 3e 4b 55 80 40 00 0c 18 28 34 3e 48 54 80 40 00 04 01 ff 40 00 40 00 40 00 40 00 40 00 40 00 40 00 40 00 00 00 00 00 00 00 00 00 00 00 1e 08 64 00 64 00 00 00 c8 00 c8 00 c8 00 2c 01 2c 01 04 04 03 04 04 04 04 04 06 06 06 06 06 07 07 08 80 08 64 00 64 00 64 00 c8 00 c8 00 c8 00 2c 01 2c 01 0e 0e 0e 0e 0e 0e 0d 0c 64 00 64 00 64 00 64 00 64 00 64 00 64 00 64 00 41 00 46 00 46 00 46 00 46 00 46 00 41 00 41 00 08 10 03 05 3f 03 b0 04 01 01 01 01 20 ff ff 00 10 08 04 08 04 02 00 00 00 00 10 20 40 50 80 40 84 03 00 00 84 03 00 00 10 10 20 20 10 10 10 10 10 10 10 10 00 19 2d 80 40 18 00 0a 14 1e 2c 3e 4b 55 80 40 00 0c 18 28 34 3e 48 54 80 40 00 04 01 ff 40 00 40 00 40 00 40 00 40 00 40 00 40 00 40 00 00 00 00 00 00 00 00 00 00 00 3c 08 78 00 78 00 00 00 f0 00 f0 00 f0 00 68 01 68 01 04 04 03 04 04 04 04 04 06 06 06 06 06 07 07 08 80 08 64 00 64 00 64 00 c8 00 c8 00 c8 00 2c 01 2c 01 12 12 12 12 12 12 11 10 64 00 64 00 64 00 64 00 64 00 64 00 64 00 64 00 4b 00 50 00 50 00 50 00 50 00 50 00 4b 00 4b 00 08 10 03 05 3f 03 14 05 01 01 01 01 30 ff ff 00 10 08 04 08 04 02 00 00 00 00 20 40 5a 5a 80 40 84 03 00 00 84 03 00 00 10 10 20 20 10 10 10 10 10 10 10 10 00 1e 32 80 40 20 00 09 12 1d 2c 38 44 51 80 40 00 0b 16 20 2e 38 45 50 80 40 00 04 01 ff 40 00 40 00 40 00 40 00 40 00 40 00 40 00 40 00 00 00 00 00 00 00 00 00 00 00 64 08 96 00 96 00 00 00 2c 01 2c 01 2c 01 c2 01 c2 01 04 04 03 04 04 04 04 04 06 06 06 06 06 07 07 08 8c 08 64 00 64 00 64 00 c8 00 c8 00 c8 00 2c 01 2c 01 14 14 14 14 14 14 13 12 64 00 64 00 64 00 64 00 64 00 64 00 64 00 64 00 4b 00 50 00 50 00 50 00 50 00 50 00 4b 00 4b 00 08 10 03 05 3f 03 78 05 01 01 01 01 40 ff ff 00 20 10 08 10 08 04 00 00 00 00 32 46 5a 6e 80 40 e8 03 00 00 e8 03 00 00 10 10 20 20 10 10 10 10 10 10 10 10 00 1e 32 80 40 20 00 08 10 1f 29 37 41 4d 80 40 00 0a 14 1e 28 32 3c 46 80 40 00 04 01 ff 40 00 40 00 40 00 40 00 40 00 40 00 40 00 40 00 00 00 00 00 00 00 00 00 00 00 8c 08 c8 00 c8 00 00 00 90 01 90 01 90 01 58 02 58 02 04 04 03 04 04 04 04 04 06 06 06 06 06 07 07 08 a0 07 64 00 64 00 64 00 c8 00 c8 00 c8 00 2c 01 2c 01 16 16 16 16 16 16 15 14 64 00 64 00 64 00 64 00 64 00 64 00 64 00 64 00 50 00 50 00 50 00 50 00 50 00 50 00 4b 00 4b 00 08 10 03 05 3f 03 dc 05 01 01 01 01 60 ff ff 00 20 10 08 10 08 04 00 00 00 00 3c 50 64 78 80 40 b0 04 00 00 b0 04 00 00 10 10 20 20 10 10 10 10 10 10 10 10 00 1e 32 80 40 20 00 06 11 1c 29 37 41 4d 80 40 00 08 11 1c 28 34 3e 47 80 40 00 04 01 f0 40 00 40 00 40 00 40 00 40 00 40 00 40 00 40 00 01 01 01 01 01 01 01 01 00 00 a0 08 2c 01 2c 01 00 00 58 02 58 02 58 02 20 03 20 03 04 04 03 04 04 04 04 04 06 06 06 06 06 07 07 08 b4 05 64 00 64 00 64 00 c8 00 c8 00 c8 00 2c 01 2c 01 1d 1d 1d 1c 1c 1c 1b 1b e6 00 e6 00 e6 00 d2 00 d2 00 d2 00 b4 00 b4 00 5f 00 5f 00 5f 00 5a 00 5a 00 5a 00 55 00 55 00 08 10 03 20 3f 04 d0 07 01 01 01 01 80 ff ff 20 20 10 08 10 08 04 14 14 20 00 5a 64 6e 78 80 40 78 05 00 00 78 05 00 00 10 10 20 20 10 10 10 10 10 10 10 10 00 30 40 80 40 20 00 04 0e 19 26 32 3c 47 80 20 00 07 10 18 20 2b 33 3b 80 40 00 04 01 dc 40 00 40 00 40 00 40 00 40 00 40 00 40 00 40 00 03 03 03 03 03 03 03 03 00 00 b4 08 f4 01 f4 01 00 00 bc 02 bc 02 bc 02 e8 03 e8 03 02 02 01 02 02 02 02 02 04 05 05 05 06 06 06 06 b4 04 64 00 64 00 64 00 c8 00 c8 00 c8 00 90 01 90 01 18 18 19 19 1a 17 17 17 dc 00 aa 00 be 00 be 00 c8 00 c8 00 c8 00 c8 00 69 00 69 00 64 00 64 00 64 00 5a 00 5a 00 5a 00 0e 12 03 20 3f 04 d0 07 01 02 02 01 80 ff ff 20 28 0a 0a 14 0a 05 14 14 40 00 64 64 64 6e 32 10 d0 07 00 00 d0 07 00 00 10 10 20 20 10 10 10 10 10 10 10 10 01 28 3c 80 40 20 00 03 0a 12 1b 23 28 2e 80 40 00 06 0a 10 15 1b 23 29 80 40 00 04 01 dc 40 00 40 00 40 00 40 00 40 00 40 00 40 00 40 00 03 03 03 03 03 03 03 03 00 00 c8 08 f4 01 f4 01 00 00 bc 02 bc 02 bc 02 e8 03 e8 03 02 02 01 02 02 02 02 02 08 08 08 09 09 09 0a 0a b4 03 64 00 64 00 64 00 c8 00 c8 00 c8 00 90 01 90 01 1e 1e 1d 1d 1d 1c 1a 1a 96 00 64 00 78 00 78 00 82 00 82 00 82 00 82 00 5f 00 5f 00 5a 00 5a 00 5a 00 50 00 50 00 50 00 12 16 03 20 3f 04 08 07 01 02 02 01 ff ff ff 40 28 0a 0a 14 0a 05 14 14 40 00 78 82 82 8c 80 40 d0 07 00 00 c4 09 00 00 10 10 20 20 10 10 10 10 10 10 10 10 00 28 3c b4 60 40 00 02 04 0c 12 1b 22 2e 80 40 00 04 08 0e 13 1a 1f 24 80 40 00 04 01 dc 40 00 40 00 40 00 40 00 40 00 40 00 40 00 40 00 03 03 03 03 03 03 03 03 00 00 c8 08 f4 01 f4 01 00 00 bc 02 bc 02 bc 02 e8 03 e8 03 01 01 00 01 01 01 01 01 08 08 08 09 09 09 0a 0a b4 03 64 00 64 00 64 00 c8 00 c8 00 c8 00 90 01 90 01 1e 1e 1d 1d 1d 1c 1a 1a 96 00 64 00 78 00 78 00 82 00 82 00 82 00 82 00 73 00 73 00 6e 00 6e 00 6e 00 64 00 64 00 64 00 12 16 03 20 3f 04 08 07 01 02 02 01 ff ff ff 40 28 0a 0a 14 0a 05 00 00 00 00 78 82 82 8c 80 40 d0 07 00 00 c4 09 00 00 10 10 20 20 10 10 10 10 10 10 10 10 00 28 3c b4 60 40 00 02 04 10 18 23 28 2e 80 40 00 04 08 10 1f 20 23 29 80 40 00 04 01 ff 40 00 40 00 40 00 40 00 40 00 40 00 40 00 40 00 00 00 00 00 00 00 00 00 00 00 c8 08 f4 01 f4 01 00 00 bc 02 bc 02 bc 02 e8 03 e8 03 01 01 00 01 01 01 01 01 08 08 08 09 09 09 0a 0a b4 03 64 00 64 00 64 00 c8 00 c8 00 c8 00 90 01 90 01 1e 1e 1d 1d 1d 1c 1a 1a 96 00 64 00 78 00 78 00 82 00 82 00 82 00 82 00 73 00 73 00 6e 00 6e 00 6e 00 64 00 64 00 64 00 12 16 03 20 3f 04 08 07 01 02 02 01 ff ff ff 40 28 0a 0a 14 0a 05 00 00 00 00 78 82 82 8c 80 40 d0 07 00 00 c4 09 00 00 10 10 20 20 10 10 10 10 10 10 10 10 00 28 3c b4 60 40 00 02 04 10 18 23 28 2e 80 40 00 04 08 10 1f 20 23 29 80 40 00 04 01 ff 40 00 40 00 40 00 40 00 40 00 40 00 40 00 40 00 00 00 00 00 00 00 00 00 00 00 c8 08 f4 01 f4 01 00 00 bc 02 bc 02 bc 02 e8 03 e8 03 01 01 00 01 01 01 01 01 08 08 08 09 09 09 0a 0a b4 03 64 00 64 00 64 00 c8 00 c8 00 c8 00 90 01 90 01 1e 1e 1d 1d 1d 1c 1a 1a 96 00 64 00 78 00 78 00 82 00 82 00 82 00 82 00 73 00 73 00 6e 00 6e 00 6e 00 64 00 64 00 64 00 12 16 03 20 3f 04 08 07 01 02 02 01 ff ff ff 40 28 0a 0a 14 0a 05 00 00 00 00 78 82 82 8c 80 40 d0 07 00 00 c4 09 00 00 10 10 20 20 10 10 10 10 10 10 10 10 00 28 3c b4 60 40 00 02 04 10 18 23 28 2e 80 40 00 04 08 10 1f 20 23 29 80 40 00 04 01 ff 40 00 40 00 40 00 40 00 40 00 40 00 40 00 40 00 00 00 00 00 00 00 00 00 00 00 c8 08 f4 01 f4 01 00 00 bc 02 bc 02 bc 02 e8 03 e8 03 01 01 00 01 01 01 01 01 08 08 08 09 09 09 0a 0a b4 03 64 00 64 00 64 00 c8 00 c8 00 c8 00 90 01 90 01 1e 1e 1d 1d 1d 1c 1a 1a 96 00 64 00 78 00 78 00 82 00 82 00 82 00 82 00 73 00 73 00 6e 00 6e 00 6e 00 64 00 64 00 64 00 12 16 03 20 3f 04 08 07 01 02 02 01 ff ff ff 40 28 0a 0a 14 0a 05 00 00 00 00 78 82 82 8c 80 40 d0 07 00 00 c4 09 00 00 10 10 20 20 10 10 10 10 10 10 10 10 00 28 3c b4 60 40 00 02 04 10 18 23 28 2e 80 40 00 04 08 10 1f 20 23 29 80 40 00 04 01 ff 40 00 40 00 40 00 40 00 40 00 40 00 40 00 40 00 00 00 00 00 00 00 00 00 00 00];
		};
		iq_pfr {
			size = [d0 00 00 00];
			data = [00 00 00 00 00 00 00 00 00 00 00 08 70 e8 ff ff ff ff ff ff ff 00 00 00 01 00 00 00 af 00 00 00 91 00 00 00 01 00 00 00 91 00 00 00 af 00 00 00 00 00 00 00 50 00 00 00 74 00 00 00 00 00 00 00 74 00 00 00 50 00 00 00 e0 00 00 00 2c 01 00 00 e0 00 00 00 2c 01 00 00 e0 00 00 00 2c 01 00 00 e0 00 00 00 2c 01 00 00 e0 00 00 00 2c 01 00 00 e0 00 00 00 2c 01 00 00 e0 00 00 00 2c 01 00 00 e0 00 00 00 2c 01 00 00 e0 00 00 00 2c 01 00 00 e0 00 00 00 2c 01 00 00 e0 00 00 00 2c 01 00 00 e0 00 00 00 2c 01 00 00 e0 00 00 00 2c 01 00 00 e0 00 00 00 2c 01 00 00 e0 00 00 00 2c 01 00 00 e0 00 00 00 2c 01 00 00 e0 00 00 00 2c 01 00 00];
		};
		iq_wdr {
			size = [88 01 00 00];
			data = [01 00 00 00 00 00 00 00 20 00 00 00 12 00 00 00 05 00 00 00 05 00 00 00 b4 40 80 00 00 01 ff 0f ff 0f ff 0f ff 0f ff 0f ff 0f ff 0f ff 0f ff 0f ff 0f ff 0f ff 0f ff 0f ff 0f ff 0f ff 0f ff 0f fe 0f fe 0f fd 0f fc 0f fa 0f f9 0f f6 0f f3 0f f0 0f eb 0f e5 0f de 0f d5 0f cb 0f bf 0f b0 0f 9f 0f 8b 0f 74 0f 5a 0f 3c 0f 1a 0f f4 0e cb 0e 9d 0e 6c 0e 37 0e fe 0d c3 0d 85 0d 44 0d 03 0d c0 0c 7d 0c 3a 0c f8 0b b7 0b 78 0b 3c 0b 01 0b ca 0a 95 0a 63 0a 34 0a 09 0a e0 09 ba 09 96 09 96 09 23 09 d0 08 96 08 6d 08 50 08 3b 08 2c 08 21 08 19 08 13 08 0f 08 0c 08 09 08 07 08 06 08 05 08 00 00 80 00 00 00 a0 00 00 00 00 00 00 00 ff 00 00 00 a0 00 00 00 00 00 00 00 ff 00 00 00 a0 00 00 00 00 00 00 00 ff 00 00 00 8c 00 00 00 00 00 00 00 ff 00 00 00 78 00 00 00 00 00 00 00 ff 00 00 00 64 00 00 00 00 00 00 00 ff 00 00 00 50 00 00 00 00 00 00 00 80 00 00 00 28 00 00 00 00 00 00 00 40 00 00 00 00 00 00 00 00 00 00 00 30 00 00 00 00 00 00 00 00 00 00 00 30 00 00 00 00 00 00 00 00 00 00 00 30 00 00 00 00 00 00 00 00 00 00 00 30 00 00 00 00 00 00 00 00 00 00 00 30 00 00 00 00 00 00 00 00 00 00 00 30 00 00 00 00 00 00 00 00 00 00 00 30 00 00 00 00 00 00 00 00 00 00 00 30 00 00 00];
		};
		iq_wdr_enh {
			size = [48 00 00 00];
			data = [01 00 00 00 80 00 00 00 80 00 00 00 80 00 00 00 80 00 00 00 80 00 00 00 80 00 00 00 80 00 00 00 80 00 00 00 80 00 00 00 80 00 00 00 80 00 00 00 80 00 00 00 80 00 00 00 80 00 00 00 80 00 00 00 80 00 00 00 80 00 00 00];
		};
		iq_defog {
			size = [84 00 00 00];
			data = [00 00 00 00 01 00 00 00 01 00 00 00 07 06 00 03 ff 60 c0 c0 c0 c0 c0 c0 c0 c0 c0 c0 c0 c0 c0 c0 c0 c0 c0 00 28 00 00 03 ff 80 28 00 00 03 ff 80 28 00 00 03 ff 80 28 00 00 03 ff 80 28 00 00 03 ff 80 28 00 00 03 ff 80 28 00 00 03 ff 80 28 00 00 03 ff 80 28 00 00 03 ff 80 28 00 00 03 ff 80 28 00 00 03 ff 80 28 00 00 03 ff 80 28 00 00 03 ff 80 28 00 00 03 ff 80 28 00 00 03 ff 80 28 00 00 03 ff 80];
		};
		iq_shdr {
			size = [64 02 00 00];
			data = [00 00 00 00 00 00 00 00 00 00 00 00 01 00 00 00 00 0c 00 02 c0 00 40 00 01 00 00 00 00 0c 00 02 c0 00 40 00 05 00 01 02 03 04 05 06 07 08 09 0a 0b 0c 0d 0e 10 00 00 00 00 00 00 00 04 00 00 00 00 00 00 00 00 00 00 00 00 00 00 00 00 00 00 00 00 00 00 00 38 1a 00 00 70 34 00 00 a7 4e 00 00 df 68 00 00 22 74 00 00 65 7f 00 00 a7 8a 00 00 ea 95 00 00 2e 9c 00 00 71 a2 00 00 b5 a8 00 00 f8 ae 00 00 f5 b2 00 00 f2 b6 00 00 ef ba 00 00 ec be 00 00 b0 c1 00 00 73 c4 00 00 37 c7 00 00 fa c9 00 00 01 cc 00 00 09 ce 00 00 10 d0 00 00 17 d2 00 00 a5 d3 00 00 33 d5 00 00 c0 d6 00 00 4e d8 00 00 89 d9 00 00 c3 da 00 00 fe db 00 00 38 dd 00 00 38 de 00 00 37 df 00 00 37 e0 00 00 36 e1 00 00 0a e2 00 00 de e2 00 00 b1 e3 00 00 85 e4 00 00 38 e5 00 00 eb e5 00 00 9e e6 00 00 51 e7 00 00 eb e7 00 00 84 e8 00 00 1e e9 00 00 b7 e9 00 00 3d ea 00 00 c2 ea 00 00 48 eb 00 00 cd eb 00 00 43 ec 00 00 b8 ec 00 00 2e ed 00 00 a3 ed 00 00 0c ee 00 00 75 ee 00 00 dd ee 00 00 46 ef 00 00 a5 ef 00 00 03 f0 00 00 62 f0 00 00 c0 f0 00 00 c0 f0 00 00 18 f2 00 00 54 f3 00 00 79 f4 00 00 8a f5 00 00 8d f6 00 00 83 f7 00 00 6f f8 00 00 52 f9 00 00 2f fa 00 00 08 fb 00 00 de fb 00 00 b1 fc 00 00 84 fd 00 00 56 fe 00 00 2a ff 00 00 ff ff 00 00 04 00 05 00 06 00 07 00 08 00 08 00 04 00 05 00 06 00 07 00 08 00 08 00 04 00 05 00 06 00 07 00 08 00 08 00 04 00 05 00 06 00 07 00 08 00 08 00 04 00 05 00 06 00 07 00 08 00 08 00 04 00 05 00 06 00 07 00 08 00 08 00 04 00 05 00 06 00 07 00 08 00 08 00 04 00 05 00 06 00 07 00 08 00 08 00 04 00 05 00 06 00 07 00 08 00 08 00 04 00 05 00 06 00 07 00 08 00 08 00 04 00 05 00 06 00 07 00 08 00 08 00 04 00 05 00 06 00 07 00 08 00 08 00 04 00 05 00 06 00 07 00 08 00 08 00 04 00 05 00 06 00 07 00 08 00 08 00 04 00 05 00 06 00 07 00 08 00 08 00 04 00 05 00 06 00 07 00 08 00 08 00 04 00 05 00 06 00 07 00 08 00 08 00];
		};
		iq_companding {
			size = [8c 03 00 00];
			data = [00 00 00 00 00 02 00 00 00 03 00 00 00 0a 00 00 ff 0f 00 00 ff 0f 00 00 ff 0f 00 00 ff 0f 00 00 ff 0f 00 00 ff 0f 00 00 ff 0f 00 00 ff 0f 00 00 ff 0f 00 00 ff 0f 00 00 ff 0f 00 00 ff 0f 00 00 ff 0f 00 00 ff 0f 00 00 ff 0f 00 00 ff 0f 00 00 ff 0f 00 00 ff 0f 00 00 ff 0f 00 00 ff 0f 00 00 ff 0f 00 00 ff 0f 00 00 ff 0f 00 00 ff 0f 00 00 ff 0f 00 00 ff 0f 00 00 ff 0f 00 00 ff 0f 00 00 00 00 00 00 00 04 00 00 00 08 00 00 00 40 00 00 ff ff 00 00 ff ff 00 00 ff ff 00 00 ff ff 00 00 ff ff 00 00 ff ff 00 00 ff ff 00 00 ff ff 00 00 ff ff 00 00 ff ff 00 00 ff ff 00 00 ff ff 00 00 ff ff 00 00 ff ff 00 00 ff ff 00 00 ff ff 00 00 ff ff 00 00 ff ff 00 00 ff ff 00 00 ff ff 00 00 ff ff 00 00 ff ff 00 00 ff ff 00 00 ff ff 00 00 ff ff 00 00 ff ff 00 00 ff ff 00 00 ff ff 00 00 01 00 00 00 01 00 00 00 01 00 00 00 01 00 00 00 01 00 00 00 01 00 00 00 01 00 00 00 01 00 00 00 01 00 00 00 01 00 00 00 01 00 00 00 01 00 00 00 01 00 00 00 01 00 00 00 01 00 00 00 01 00 00 00 01 00 00 00 01 00 00 00 01 00 00 00 01 00 00 00 01 00 00 00 01 00 00 00 01 00 00 00 01 00 00 00 01 00 00 00 01 00 00 00 01 00 00 00 01 00 00 00 01 00 00 00 01 00 00 00 01 00 00 00 01 00 00 00 04 00 00 00 05 00 00 00 06 00 00 00 08 00 00 00 08 00 00 00 08 00 00 00 08 00 00 00 08 00 00 00 08 00 00 00 08 00 00 00 08 00 00 00 08 00 00 00 08 00 00 00 08 00 00 00 08 00 00 00 08 00 00 00 08 00 00 00 08 00 00 00 08 00 00 00 08 00 00 00 08 00 00 00 08 00 00 00 08 00 00 00 08 00 00 00 08 00 00 00 08 00 00 00 08 00 00 00 08 00 00 00 08 00 00 00 08 00 00 00 08 00 00 00 08 00 00 00 00 00 00 00 a3 01 00 00 47 03 00 00 ea 04 00 00 8d 06 00 00 42 07 00 00 f6 07 00 00 aa 08 00 00 5e 09 00 00 c2 09 00 00 27 0a 00 00 8b 0a 00 00 ef 0a 00 00 2f 0b 00 00 6f 0b 00 00 ae 0b 00 00 ee 0b 00 00 1b 0c 00 00 47 0c 00 00 73 0c 00 00 9f 0c 00 00 c0 0c 00 00 e0 0c 00 00 01 0d 00 00 21 0d 00 00 3a 0d 00 00 53 0d 00 00 6c 0d 00 00 84 0d 00 00 98 0d 00 00 ac 0d 00 00 bf 0d 00 00 d3 0d 00 00 e3 0d 00 00 f3 0d 00 00 03 0e 00 00 13 0e 00 00 20 0e 00 00 2d 0e 00 00 3b 0e 00 00 48 0e 00 00 53 0e 00 00 5e 0e 00 00 69 0e 00 00 75 0e 00 00 7e 0e 00 00 88 0e 00 00 91 0e 00 00 9b 0e 00 00 a3 0e 00 00 ac 0e 00 00 b4 0e 00 00 bc 0e 00 00 c4 0e 00 00 cb 0e 00 00 d2 0e 00 00 da 0e 00 00 e0 0e 00 00 e7 0e 00 00 ed 0e 00 00 f4 0e 00 00 fa 0e 00 00 00 0f 00 00 06 0f 00 00 0c 0f 00 00 0c 0f 00 00 21 0f 00 00 35 0f 00 00 47 0f 00 00 58 0f 00 00 68 0f 00 00 78 0f 00 00 86 0f 00 00 95 0f 00 00 a2 0f 00 00 b0 0f 00 00 bd 0f 00 00 cb 0f 00 00 d8 0f 00 00 e5 0f 00 00 f2 0f 00 00 ff 0f 00 00 ff 0f 00 00 ff 0f 00 00 ff 0f 00 00 ff 0f 00 00 ff 0f 00 00 ff 0f 00 00 ff 0f 00 00 ff 0f 00 00 ff 0f 00 00 ff 0f 00 00 ff 0f 00 00 ff 0f 00 00 ff 0f 00 00 ff 0f 00 00 ff 0f 00 00 ff 0f 00 00 00 00 00 00];
		};
		iq_rgbir {
			size = [2c 00 00 00];
			data = [01 00 00 00 00 00 00 00 cc 00 00 00 cc 00 00 00 e6 00 00 00 00 01 00 00 cc 00 00 00 cc 00 00 00 e6 00 00 00 dc 00 00 00 f0 00 00 00];
		};
		iq_rgbir_enh {
			size = [28 01 00 00];
			data = [01 00 00 00 00 00 00 00 32 00 00 00 10 00 00 00 10 00 00 00 10 00 00 00 10 00 00 00 10 00 00 00 10 00 00 00 10 00 00 00 10 00 00 00 10 00 00 00 10 00 00 00 10 00 00 00 10 00 00 00 10 00 00 00 10 00 00 00 10 00 00 00 10 00 00 00 ff ff 00 00 80 00 00 00 20 00 00 00 20 00 00 00 20 00 00 00 20 00 00 00 20 00 00 00 20 00 00 00 20 00 00 00 20 00 00 00 20 00 00 00 20 00 00 00 20 00 00 00 20 00 00 00 20 00 00 00 20 00 00 00 20 00 00 00 20 00 00 00 ff ff 00 00 98 00 00 00 50 00 00 00 50 00 00 00 50 00 00 00 50 00 00 00 50 00 00 00 50 00 00 00 50 00 00 00 50 00 00 00 50 00 00 00 50 00 00 00 50 00 00 00 50 00 00 00 50 00 00 00 50 00 00 00 50 00 00 00 50 00 00 00 ff ff 00 00 ff 00 00 00 a0 00 00 00 a0 00 00 00 a0 00 00 00 a0 00 00 00 a0 00 00 00 a0 00 00 00 a0 00 00 00 a0 00 00 00 a0 00 00 00 a0 00 00 00 a0 00 00 00 a0 00 00 00 a0 00 00 00 a0 00 00 00 a0 00 00 00 a0 00 00 00 ff ff 00 00];
		};
		iq_post_sharpen_1 {
			size = [b0 02 00 00];
			data = [00 00 00 00 00 00 00 00 19 23 23 23 23 23 23 23 23 23 23 23 23 23 23 23 23 23 02 ff fa 00 5e 01 50 50 80 50 ff 00 40 00 00 00 00 00 50 80 80 00 19 23 23 23 23 23 23 23 23 23 23 23 23 23 23 23 23 23 02 ff 96 00 fa 00 20 50 80 50 ff 00 40 00 00 00 00 00 50 80 80 00 19 23 23 23 23 23 23 23 23 23 23 23 23 23 23 23 23 23 02 ff 96 00 fa 00 50 50 80 50 ff 00 40 00 00 00 00 00 50 80 80 00 19 23 23 23 23 23 23 23 23 23 23 23 23 23 23 23 23 23 02 ff 96 00 fa 00 50 50 80 50 ff 00 40 00 00 00 00 00 50 80 80 00 19 23 23 23 23 23 23 23 23 23 23 23 23 23 23 23 23 23 02 ff 96 00 fa 00 50 50 80 50 ff 00 40 00 00 00 00 00 50 80 80 00 19 23 23 23 23 23 23 23 23 23 23 23 23 23 23 23 23 23 02 ff 96 00 fa 00 50 50 80 50 ff 00 40 00 00 00 00 00 50 80 80 00 19 23 23 23 23 23 23 23 23 23 23 23 23 23 23 23 23 23 02 ff 96 00 fa 00 50 50 80 50 ff 00 40 00 00 00 00 00 50 80 80 00 19 23 23 23 23 23 23 23 23 23 23 23 23 23 23 23 23 23 02 ff 96 00 fa 00 50 50 80 50 ff 00 40 00 00 00 00 00 50 80 80 00 19 23 23 23 23 23 23 23 23 23 23 23 23 23 23 23 23 23 02 ff 96 00 fa 00 50 50 80 50 ff 00 40 00 00 00 00 00 50 80 80 00 19 23 23 23 23 23 23 23 23 23 23 23 23 23 23 23 23 23 02 ff 64 00 c8 00 50 50 80 50 ff 00 40 00 00 00 00 00 50 80 80 00 19 23 23 23 23 23 23 23 23 23 23 23 23 23 23 23 23 23 02 ff 64 00 c8 00 50 50 80 50 ff 00 40 00 00 00 00 00 50 80 80 00 69 23 23 23 23 23 23 23 23 23 23 23 23 23 23 23 23 23 02 ff 64 00 c8 00 50 50 80 50 ff 00 40 00 00 00 00 00 50 80 80 00 69 23 23 23 23 23 23 23 23 23 23 23 23 23 23 23 23 23 02 ff 64 00 c8 00 50 50 80 50 ff 00 40 00 00 00 00 00 50 80 80 00 69 23 23 23 23 23 23 23 23 23 23 23 23 23 23 23 23 23 02 ff 64 00 c8 00 50 50 80 50 ff 00 40 00 00 00 00 00 50 80 80 00 69 23 23 23 23 23 23 23 23 23 23 23 23 23 23 23 23 23 02 ff 64 00 c8 00 50 50 80 50 ff 00 40 00 00 00 00 00 50 80 80 00 69 23 23 23 23 23 23 23 23 23 23 23 23 23 23 23 23 23 02 ff 64 00 c8 00 50 50 80 50 ff 00 40 00 00 00 00 00 50 80 80 00 69 23 23 23 23 23 23 23 23 23 23 23 23 23 23 23 23 23 02 ff 64 00 c8 00 50 50 80 50 ff 00 40 00 00 00 00 00 50 80 80 00];
		};
		iq_post_sharpen_2 {
			size = [4c 02 00 00];
			data = [01 00 00 00 00 00 00 00 19 23 23 23 23 23 23 23 23 23 23 23 23 23 23 23 23 23 02 ff 32 00 64 00 50 50 80 50 ff 00 40 50 80 80 19 23 23 23 23 23 23 23 23 23 23 23 23 23 23 23 23 23 02 ff 46 00 78 00 50 80 80 50 ff 00 40 40 80 80 19 23 23 23 23 23 23 23 23 23 23 23 23 23 23 23 23 23 02 ff 50 00 8c 00 50 80 80 50 ff 00 40 40 80 80 19 23 23 23 23 23 23 23 23 23 23 23 23 23 23 23 23 23 02 ff 50 00 82 00 50 80 80 50 ff 00 40 40 80 80 19 23 23 23 23 23 23 23 23 23 23 23 23 23 23 23 23 23 02 ff 50 00 82 00 50 80 80 50 ff 00 40 40 80 80 19 23 23 23 23 23 23 23 23 23 23 23 23 23 23 23 23 23 02 ff 5a 00 8c 00 50 80 80 50 ff 00 40 40 80 80 19 23 23 23 23 23 23 23 23 23 23 23 23 23 23 23 23 23 02 ff 64 00 96 00 50 80 80 50 ff 00 40 40 80 80 19 23 23 23 23 23 23 23 23 23 23 23 23 23 23 23 23 23 02 ff 78 00 c8 00 50 80 80 50 ff 00 40 40 80 80 19 23 23 23 23 23 23 23 23 23 23 23 23 23 23 23 23 23 02 ff 96 00 2c 01 50 80 80 50 ff 00 40 40 80 80 19 23 23 23 23 23 23 23 23 23 23 23 23 23 23 23 23 23 02 ff aa 00 40 01 50 80 80 50 ff 00 40 40 80 80 19 23 23 23 23 23 23 23 23 23 23 23 23 23 23 23 23 23 02 ff b4 00 4a 01 50 80 80 50 ff 00 40 40 80 80 69 23 23 23 23 23 23 23 23 23 23 23 23 23 23 23 23 23 02 ff 2c 01 c2 01 50 80 80 50 ff 00 40 40 80 80 69 23 23 23 23 23 23 23 23 23 23 23 23 23 23 23 23 23 02 ff 2c 01 c2 01 50 80 80 50 ff 00 40 40 80 80 69 23 23 23 23 23 23 23 23 23 23 23 23 23 23 23 23 23 02 ff 2c 01 c2 01 50 80 80 50 ff 00 40 40 80 80 69 23 23 23 23 23 23 23 23 23 23 23 23 23 23 23 23 23 02 ff 2c 01 c2 01 50 80 80 50 ff 00 40 40 80 80 69 23 23 23 23 23 23 23 23 23 23 23 23 23 23 23 23 23 02 ff 2c 01 c2 01 50 80 80 50 ff 00 40 40 80 80 69 23 23 23 23 23 23 23 23 23 23 23 23 23 23 23 23 23 02 ff 2c 01 c2 01 50 80 80 50 ff 00 40 40 80 80 00 00];
		};
		iq_ycurve {
			size = [08 02 00 00];
			data = [00 00 00 00 00 00 00 00 02 00 00 00 04 00 00 00 06 00 00 00 08 00 00 00 0a 00 00 00 0c 00 00 00 0e 00 00 00 10 00 00 00 12 00 00 00 14 00 00 00 16 00 00 00 18 00 00 00 1a 00 00 00 1c 00 00 00 1e 00 00 00 20 00 00 00 22 00 00 00 24 00 00 00 26 00 00 00 28 00 00 00 2a 00 00 00 2c 00 00 00 2e 00 00 00 30 00 00 00 32 00 00 00 34 00 00 00 36 00 00 00 38 00 00 00 3a 00 00 00 3c 00 00 00 3e 00 00 00 40 00 00 00 42 00 00 00 44 00 00 00 46 00 00 00 48 00 00 00 4a 00 00 00 4c 00 00 00 4e 00 00 00 50 00 00 00 52 00 00 00 54 00 00 00 56 00 00 00 58 00 00 00 5a 00 00 00 5c 00 00 00 5e 00 00 00 60 00 00 00 62 00 00 00 64 00 00 00 66 00 00 00 68 00 00 00 6a 00 00 00 6c 00 00 00 6e 00 00 00 70 00 00 00 72 00 00 00 74 00 00 00 76 00 00 00 78 00 00 00 7a 00 00 00 7c 00 00 00 7e 00 00 00 80 00 00 00 82 00 00 00 84 00 00 00 86 00 00 00 88 00 00 00 8a 00 00 00 8c 00 00 00 8e 00 00 00 90 00 00 00 92 00 00 00 94 00 00 00 96 00 00 00 98 00 00 00 9a 00 00 00 9c 00 00 00 9e 00 00 00 a0 00 00 00 a2 00 00 00 a4 00 00 00 a6 00 00 00 a8 00 00 00 aa 00 00 00 ac 00 00 00 ae 00 00 00 b0 00 00 00 b2 00 00 00 b4 00 00 00 b6 00 00 00 b8 00 00 00 ba 00 00 00 bc 00 00 00 be 00 00 00 c0 00 00 00 c2 00 00 00 c4 00 00 00 c6 00 00 00 c8 00 00 00 ca 00 00 00 cc 00 00 00 ce 00 00 00 d0 00 00 00 d2 00 00 00 d4 00 00 00 d6 00 00 00 d8 00 00 00 da 00 00 00 dc 00 00 00 de 00 00 00 e0 00 00 00 e2 00 00 00 e4 00 00 00 e6 00 00 00 e8 00 00 00 ea 00 00 00 ec 00 00 00 ee 00 00 00 f0 00 00 00 f2 00 00 00 f4 00 00 00 f6 00 00 00 f8 00 00 00 fa 00 00 00 fc 00 00 00 fe 00 00 00 ff 00 00 00];
		};
		iq_cst {
			size = [2c 00 00 00];
			data = [00 00 00 00 4d 00 96 00 1d 00 d5 ff ab ff 80 00 80 00 95 ff eb ff 00 00 80 80 02 02 02 02 02 02 02 02 02 02 02 02 02 02 02 02 02 00];
		};
	};
};
